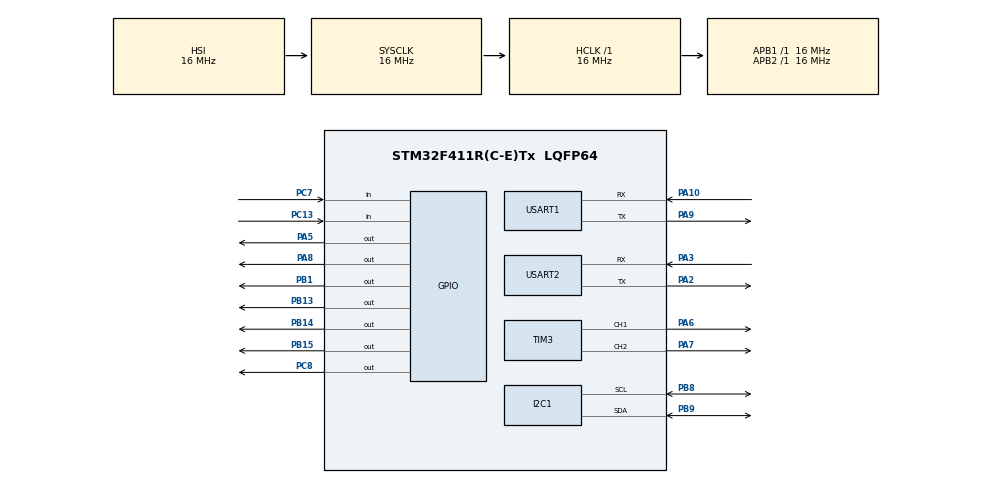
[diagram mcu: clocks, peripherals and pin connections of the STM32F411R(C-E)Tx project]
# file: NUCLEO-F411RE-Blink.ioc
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Mcu.Family=STM32F4
Mcu.Name=STM32F411R(C-E)Tx
Mcu.Package=LQFP64
NVIC.PriorityGroup=NVIC_PRIORITYGROUP_4
NVIC.USART1_IRQn=true\:0\:0\:false\:false\:true\:true\:true\:true
PA10.Mode=Asynchronous
PA10.Signal=USART1_RX
PA2.Mode=Asynchronous
PA2.Signal=USART2_TX
PA3.Mode=Asynchronous
PA3.Signal=USART2_RX
PA5.Signal=GPIO_Output
PA6.Signal=S_TIM3_CH1
PA7.Signal=S_TIM3_CH2
PA8.Signal=GPIO_Output
PA9.Mode=Asynchronous
PA9.Signal=USART1_TX
PB1.Signal=GPIO_Output
PB13.Signal=GPIO_Output
PB14.Signal=GPIO_Output
PB15.Signal=GPIO_Output
PB8.Mode=I2C
PB8.Signal=I2C1_SCL
PB9.Mode=I2C
PB9.Signal=I2C1_SDA
PC13-ANTI_TAMP.Signal=GPIO_Input
PC7.Signal=GPIO_Input
PC8.Signal=GPIO_Output
ProjectManager.HeapSize=0x200
ProjectManager.StackSize=0x400
ProjectManager.TargetToolchain=STM32CubeIDE
RCC.AHBFreq_Value=16000000
RCC.APB1Freq_Value=16000000
RCC.APB2Freq_Value=16000000
RCC.CortexFreq_Value=16000000
RCC.HSE_VALUE=25000000
RCC.HSI_VALUE=16000000
RCC.LSE_VALUE=32768
RCC.SYSCLKFreq_VALUE=16000000
RCC.VCOOutputFreq_Value=192000000
SH.S_TIM3_CH1.0=TIM3_CH1,PWM Generation1 CH1
SH.S_TIM3_CH2.0=TIM3_CH2,PWM Generation2 CH2
TIM3.Channel-PWM\ Generation1\ CH1=TIM_CHANNEL_1
TIM3.Channel-PWM\ Generation2\ CH2=TIM_CHANNEL_2
USART1.VirtualMode=VM_ASYNC
USART2.VirtualMode=VM_ASYNC
VP_TIM3_VS_ClockSourceINT.Mode=Internal
board=custom

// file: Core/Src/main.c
/* USER CODE BEGIN Header */
/**
  ******************************************************************************
  * @file           : main.c
  * @brief          : Main program body
  ******************************************************************************
  */
/* USER CODE END Header */
#include "main.h"

/* USER CODE BEGIN Includes */
#include <stdio.h>
#include <string.h>
/* USER CODE END Includes */

I2C_HandleTypeDef hi2c1;

TIM_HandleTypeDef htim3;

UART_HandleTypeDef huart1;
UART_HandleTypeDef huart2;

/* USER CODE BEGIN PV */
volatile uint8_t uart1_rx_byte;
volatile char esp32_rx_buffer[256];
volatile uint8_t esp32_rx_index = 0;
volatile uint32_t uart_rx_count = 0;
volatile char cmd_rx_buffer[256];
volatile uint8_t cmd_rx_ready = 0;

volatile int target_face_x = 0;
volatile int target_face_y = 0;
volatile int face_detected = 0;
volatile uint32_t last_face_time = 0;

// Globals for Webpage Manual Control
volatile uint32_t last_manual_command_time = 0;
volatile int manual_left_speed = 0;
volatile int manual_right_speed = 0;

// Globals for Motor Acceleration Ramping (Soft Start)
volatile int target_left_speed = 0;
volatile int target_right_speed = 0;
volatile int current_left_speed = 0;
volatile int current_right_speed = 0;

// Globals for Webpage & Screen Menu Button options
volatile uint32_t button_pressed_time = 0;
volatile uint8_t button_held = 0;
volatile uint8_t face_detect_pin_state = 1; // Default ON (sets GPIOC Pin 8 to HIGH)

uint16_t sgp30_co2 = 400;
uint16_t sgp30_tvoc = 0;
/* USER CODE END PV */

void SystemClock_Config(void);
static void MX_GPIO_Init(void);
static void MX_USART2_UART_Init(void);
static void MX_I2C1_Init(void);
static void MX_TIM3_Init(void);
static void MX_USART1_UART_Init(void);
/* USER CODE BEGIN PFP */
void set_motors(int speed_left, int speed_right);
void apply_motors(int speed_left, int speed_right);

/* USER CODE END PFP */

/* USER CODE BEGIN 0 */
typedef enum {
    EMOTION_HAPPY,
    EMOTION_ANGRY,
    EMOTION_SEARCHING,
    EMOTION_DIZZY
} RobotEmotion;

RobotEmotion current_emotion = EMOTION_HAPPY;
uint32_t last_bop_time = 0;

void DWT_Delay_us(uint32_t us) {
    // Software delay calibrated for 16MHz HSI clock
    // us * 3 is roughly 1 microsecond of delay including loop overhead
    volatile uint32_t delay = us * 3;
    while (delay--);
}

int HCSR04_Read(void) {
    HAL_GPIO_WritePin(GPIOA, GPIO_PIN_8, GPIO_PIN_RESET);
    DWT_Delay_us(2);
    HAL_GPIO_WritePin(GPIOA, GPIO_PIN_8, GPIO_PIN_SET);
    DWT_Delay_us(10);
    HAL_GPIO_WritePin(GPIOA, GPIO_PIN_8, GPIO_PIN_RESET);

    // Software timeout loop instead of DWT timer
    uint32_t timeout = 0;
    while (HAL_GPIO_ReadPin(GPIOC, GPIO_PIN_7) == GPIO_PIN_RESET) {
        if (timeout++ > 50000) return -1;
    }

    uint32_t pulse_width = 0;
    while (HAL_GPIO_ReadPin(GPIOC, GPIO_PIN_7) == GPIO_PIN_SET) {
        pulse_width++;
        // Very short delay for calibration
        volatile uint32_t delay = 2;
        while(delay--);
        if (pulse_width > 60000) return -1;
    }

    // Calibrated divisor for software loop
    return pulse_width / 25;
}

void SGP30_Init(void) {
    uint8_t cmd[2] = {0x20, 0x03};
    HAL_I2C_Master_Transmit(&hi2c1, 0x58 << 1, cmd, 2, 100);
}

void SGP30_Measure(uint16_t *co2, uint16_t *tvoc) {
    uint8_t cmd[2] = {0x20, 0x08};
    HAL_I2C_Master_Transmit(&hi2c1, 0x58 << 1, cmd, 2, 100);
    HAL_Delay(12);
    uint8_t data[6];
    if (HAL_I2C_Master_Receive(&hi2c1, 0x58 << 1, data, 6, 100) == HAL_OK) {
        *co2 = (data[0] << 8) | data[1];
        *tvoc = (data[3] << 8) | data[4];
    }
}

void set_motors(int speed_left, int speed_right) {
    target_left_speed = speed_left;
    target_right_speed = speed_right;
}

void apply_motors(int speed_left, int speed_right) {
    if (speed_left > 0) {
        HAL_GPIO_WritePin(GPIOB, GPIO_PIN_13, GPIO_PIN_SET);
        HAL_GPIO_WritePin(GPIOB, GPIO_PIN_14, GPIO_PIN_RESET);
    } else if (speed_left < 0) {
        HAL_GPIO_WritePin(GPIOB, GPIO_PIN_13, GPIO_PIN_RESET);
        HAL_GPIO_WritePin(GPIOB, GPIO_PIN_14, GPIO_PIN_SET);
        speed_left = -speed_left;
    } else {
        HAL_GPIO_WritePin(GPIOB, GPIO_PIN_13, GPIO_PIN_RESET);
        HAL_GPIO_WritePin(GPIOB, GPIO_PIN_14, GPIO_PIN_RESET);
    }

    if (speed_right > 0) {
        HAL_GPIO_WritePin(GPIOB, GPIO_PIN_15, GPIO_PIN_SET);
        HAL_GPIO_WritePin(GPIOB, GPIO_PIN_1, GPIO_PIN_RESET);
    } else if (speed_right < 0) {
        HAL_GPIO_WritePin(GPIOB, GPIO_PIN_15, GPIO_PIN_RESET);
        HAL_GPIO_WritePin(GPIOB, GPIO_PIN_1, GPIO_PIN_SET);
        speed_right = -speed_right;
    } else {
        HAL_GPIO_WritePin(GPIOB, GPIO_PIN_15, GPIO_PIN_RESET);
        HAL_GPIO_WritePin(GPIOB, GPIO_PIN_1, GPIO_PIN_RESET);
    }

    if (speed_left > 999) speed_left = 999;
    if (speed_right > 999) speed_right = 999;

    // Scale 0-1000 speed range to 0-65535 PWM period of TIM3
    uint32_t compare_left = (speed_left * 65535) / 1000;
    uint32_t compare_right = (speed_right * 65535) / 1000;

    __HAL_TIM_SET_COMPARE(&htim3, TIM_CHANNEL_1, compare_left);
    __HAL_TIM_SET_COMPARE(&htim3, TIM_CHANNEL_2, compare_right);
}

void track_face() {
    if (face_detected) {
        int error = target_face_x - 160;
        int base_speed = 300;
        int turn_speed = error * 3;
        int left = base_speed + turn_speed;
        int right = base_speed - turn_speed;
        set_motors(left, right);
    } else {
        set_motors(0, 0);
    }
}

#define OLED_ADDR        (0x3C << 1)

void OLED_WriteCommand(uint8_t cmd) {
    uint8_t buffer[2];
    buffer[0] = 0x00;
    buffer[1] = cmd;
    HAL_I2C_Master_Transmit(&hi2c1, OLED_ADDR, buffer, 2, 10);
}

void OLED_Init(void) {
    HAL_Delay(200);
    OLED_WriteCommand(0xAE);
    OLED_WriteCommand(0xD5); OLED_WriteCommand(0x80);
    OLED_WriteCommand(0xA8); OLED_WriteCommand(0x3F);
    OLED_WriteCommand(0xD3); OLED_WriteCommand(0x00);
    OLED_WriteCommand(0x40);
    OLED_WriteCommand(0x8D); OLED_WriteCommand(0x14);
    OLED_WriteCommand(0x20); OLED_WriteCommand(0x00);
    OLED_WriteCommand(0xA1);
    OLED_WriteCommand(0xC8);
    OLED_WriteCommand(0xDA); OLED_WriteCommand(0x12);
    OLED_WriteCommand(0x81); OLED_WriteCommand(0x7F);
    OLED_WriteCommand(0xD9); OLED_WriteCommand(0x22);
    OLED_WriteCommand(0xDB); OLED_WriteCommand(0x20);
    OLED_WriteCommand(0xA4); OLED_WriteCommand(0xA6);
    OLED_WriteCommand(0xAF);
    HAL_Delay(10);
}

void OLED_Clear(void) {
    OLED_WriteCommand(0x21); OLED_WriteCommand(0); OLED_WriteCommand(127);
    OLED_WriteCommand(0x22); OLED_WriteCommand(0); OLED_WriteCommand(7);
    static uint8_t clear_buf[129];
    clear_buf[0] = 0x40;
    for(int i = 1; i <= 128; i++) clear_buf[i] = 0x00;
    for(int page = 0; page < 8; page++) {
        HAL_I2C_Master_Transmit(&hi2c1, OLED_ADDR, clear_buf, 129, 50);
    }
}

const uint8_t BasicFont[41][5] = {
    {0x3E, 0x51, 0x49, 0x45, 0x3E}, // 0
    {0x00, 0x42, 0x7F, 0x40, 0x00}, // 1
    {0x42, 0x61, 0x51, 0x49, 0x46}, // 2
    {0x21, 0x41, 0x45, 0x4B, 0x31}, // 3
    {0x18, 0x14, 0x12, 0x7F, 0x10}, // 4
    {0x27, 0x45, 0x45, 0x45, 0x39}, // 5
    {0x3C, 0x4A, 0x49, 0x49, 0x30}, // 6
    {0x01, 0x71, 0x09, 0x05, 0x03}, // 7
    {0x36, 0x49, 0x49, 0x49, 0x36}, // 8
    {0x06, 0x49, 0x49, 0x29, 0x1E}, // 9
    {0x7E, 0x11, 0x11, 0x11, 0x7E}, // A
    {0x7F, 0x49, 0x49, 0x49, 0x36}, // B
    {0x3E, 0x41, 0x41, 0x41, 0x22}, // C
    {0x7F, 0x41, 0x41, 0x22, 0x1C}, // D
    {0x7F, 0x49, 0x49, 0x49, 0x41}, // E
    {0x7F, 0x09, 0x09, 0x09, 0x01}, // F
    {0x3E, 0x41, 0x49, 0x49, 0x7A}, // G
    {0x7F, 0x08, 0x08, 0x08, 0x7F}, // H
    {0x00, 0x41, 0x7F, 0x41, 0x00}, // I
    {0x20, 0x40, 0x41, 0x3F, 0x01}, // J
    {0x7F, 0x08, 0x14, 0x22, 0x41}, // K
    {0x7F, 0x40, 0x40, 0x40, 0x40}, // L
    {0x7F, 0x02, 0x0C, 0x02, 0x7F}, // M
    {0x7F, 0x04, 0x08, 0x10, 0x7F}, // N
    {0x3E, 0x41, 0x41, 0x41, 0x3E}, // O
    {0x7F, 0x09, 0x09, 0x09, 0x06}, // P
    {0x3E, 0x41, 0x51, 0x21, 0x5E}, // Q
    {0x7F, 0x09, 0x19, 0x29, 0x46}, // R
    {0x46, 0x49, 0x49, 0x49, 0x31}, // S
    {0x01, 0x01, 0x7F, 0x01, 0x01}, // T
    {0x3F, 0x40, 0x40, 0x40, 0x3F}, // U
    {0x00, 0x20, 0x40, 0x20, 0x00}, // V
    {0x3F, 0x40, 0x38, 0x40, 0x3F}, // W
    {0x63, 0x14, 0x08, 0x14, 0x63}, // X
    {0x07, 0x08, 0x70, 0x08, 0x07}, // Y
    {0x61, 0x51, 0x49, 0x45, 0x43}, // Z
    {0x00, 0x00, 0x00, 0x00, 0x00}, // [Space]
    {0x00, 0x24, 0x24, 0x24, 0x00}, // :
    {0x08, 0x08, 0x08, 0x08, 0x08}, // -
    {0x41, 0x22, 0x14, 0x08, 0x00}, // >
    {0x08, 0x14, 0x22, 0x41, 0x00}  // <
};

void OLED_PrintText(uint8_t page, uint8_t col, char* str) {
    OLED_WriteCommand(0x21); OLED_WriteCommand(col); OLED_WriteCommand(127);
    OLED_WriteCommand(0x22); OLED_WriteCommand(page); OLED_WriteCommand(7);
    static uint8_t tx_buf[6];
    tx_buf[0] = 0x40;
    while(*str) {
        uint8_t idx = 36;
        char c = *str;
        if (c >= '0' && c <= '9') idx = c - '0';
        else if (c >= 'A' && c <= 'Z') idx = (c - 'A') + 10;
        else if (c >= 'a' && c <= 'z') idx = (c - 'a') + 10;
        else if (c == ':') idx = 37;
        else if (c == '-') idx = 38;
        else if (c == '>') idx = 39;
        else if (c == '<') idx = 40;
        for(int i = 0; i < 5; i++) tx_buf[i + 1] = BasicFont[idx][i];
        HAL_I2C_Master_Transmit(&hi2c1, OLED_ADDR, tx_buf, 6, 10);
        str++;
    }
}

void OLED_DrawBitmap(const uint8_t* bitmap) {
    OLED_WriteCommand(0x21); OLED_WriteCommand(0); OLED_WriteCommand(127);
    OLED_WriteCommand(0x22); OLED_WriteCommand(0); OLED_WriteCommand(7);
    static uint8_t data_buffer[1025];
    data_buffer[0] = 0x40;
    for (int i = 0; i < 1024; i++) {
        data_buffer[i + 1] = bitmap[i];
    }
    HAL_I2C_Master_Transmit(&hi2c1, OLED_ADDR, data_buffer, 1025, 200);
}

// Your updated text canvas mathematically padded to a solid 64 rows and converted to vertical page bytes
const uint8_t OLED_TrueDogBitmap[1024] = {
	0x00, 0x00, 0x00, 0x00, 0x00, 0x00, 0x00, 0x00, 0x00, 0x00, 0x00, 0x00, 0x00, 0x00, 0x00, 0x00,
	0x00, 0x00, 0x00, 0x00, 0x00, 0x00, 0x00, 0x00, 0x00, 0x00, 0x00, 0x00, 0x00, 0x00, 0x00, 0x00,
	0x00, 0x00, 0x00, 0x00, 0x00, 0x00, 0x00, 0x00, 0x00, 0x00, 0x00, 0x00, 0x00, 0x00, 0x00, 0x00,
	0x00, 0x00, 0x00, 0x00, 0x00, 0x00, 0x00, 0x00, 0x00, 0x00, 0x00, 0x00, 0x00, 0x00, 0x00, 0x00,
	0x00, 0x00, 0x00, 0x00, 0x00, 0x00, 0x00, 0x00, 0x00, 0x00, 0x00, 0x00, 0x00, 0x00, 0x00, 0x00,
	0x00, 0x00, 0x00, 0x00, 0x00, 0x00, 0x00, 0x00, 0x00, 0x00, 0x00, 0x00, 0x00, 0x00, 0x00, 0x00,
	0x00, 0x00, 0x00, 0x00, 0x00, 0x00, 0x00, 0x00, 0x00, 0x00, 0x00, 0x00, 0x00, 0x00, 0x00, 0x00,
	0x00, 0x00, 0x00, 0x00, 0x00, 0x00, 0x00, 0x00, 0x00, 0x00, 0x00, 0x00, 0x00, 0x00, 0x00, 0x00,
	0x00, 0x00, 0x00, 0x00, 0x00, 0x00, 0x00, 0x00, 0x00, 0x00, 0x00, 0x00, 0x00, 0x00, 0x00, 0x00,
	0x00, 0x00, 0x00, 0x00, 0x00, 0x00, 0x00, 0x00, 0x00, 0x00, 0x00, 0x00, 0x00, 0x00, 0x00, 0x00,
	0x00, 0x00, 0x00, 0x00, 0x00, 0x00, 0x00, 0x00, 0x00, 0x00, 0x00, 0x00, 0x00, 0x00, 0x00, 0x00,
	0x00, 0x00, 0x00, 0x00, 0x00, 0x00, 0x00, 0x00, 0x00, 0x00, 0x00, 0x00, 0x00, 0x00, 0x00, 0x00,
	0x00, 0x00, 0x00, 0x00, 0x00, 0x00, 0x00, 0x00, 0x00, 0x00, 0x00, 0x00, 0x00, 0x00, 0x00, 0x00,
	0x00, 0x00, 0xE0, 0xE0, 0xE0, 0xE0, 0xE0, 0xE0, 0xE0, 0xE0, 0xE0, 0xE0, 0xE0, 0xE0, 0xE0, 0xE0,
	0xE0, 0xE0, 0xE0, 0xE0, 0xE0, 0xE0, 0xE0, 0xE0, 0xE0, 0xE0, 0x00, 0x00, 0x00, 0x00, 0x00, 0x00,
	0x00, 0x00, 0x00, 0x00, 0x00, 0x00, 0x00, 0x00, 0x00, 0x00, 0x00, 0x00, 0x00, 0x00, 0x00, 0x00,
	0x00, 0x00, 0x00, 0x00, 0x00, 0x00, 0x00, 0x00, 0x00, 0x00, 0x00, 0x00, 0x00, 0x00, 0x00, 0x80,
	0x80, 0x80, 0x80, 0x80, 0x80, 0x80, 0x80, 0x80, 0xE0, 0xE0, 0xF0, 0xF0, 0xF0, 0xFF, 0x7F, 0x7F,
	0x7F, 0x7F, 0xFF, 0xFC, 0xFC, 0xFC, 0xFC, 0xFC, 0xFC, 0xFC, 0xFC, 0xFC, 0x83, 0x83, 0x83, 0x83,
	0xFF, 0xFF, 0xFF, 0xFF, 0xFF, 0xFF, 0x00, 0x00, 0x00, 0x00, 0x00, 0x00, 0x00, 0x00, 0x00, 0x00,
	0x00, 0x00, 0x00, 0x00, 0x00, 0x00, 0x00, 0x00, 0xFC, 0xFC, 0xFC, 0xFC, 0xFC, 0xFF, 0xFF, 0xFF,
	0xFF, 0xFF, 0xFF, 0x1F, 0x1F, 0x1F, 0x1F, 0x07, 0x07, 0x07, 0x07, 0x07, 0x07, 0x07, 0x07, 0x07,
	0x1F, 0x1F, 0x1F, 0x1F, 0x1F, 0x7F, 0x7F, 0x7F, 0x7F, 0x7F, 0x7F, 0x7F, 0x7F, 0x7F, 0x7F, 0x00,
	0x00, 0x00, 0x00, 0x00, 0x00, 0x00, 0x00, 0x00, 0x00, 0x00, 0x00, 0x00, 0x00, 0x00, 0x00, 0x00,
	0x00, 0x00, 0x00, 0x00, 0x00, 0x00, 0x00, 0x00, 0x00, 0x00, 0x00, 0x00, 0x00, 0x00, 0x00, 0x7F,
	0x3F, 0x3F, 0x3F, 0xFF, 0xFF, 0xFF, 0xFF, 0xFF, 0xFF, 0xFF, 0xFF, 0xFF, 0xFF, 0xFF, 0xF0, 0xF0,
	0xF0, 0xF0, 0xFF, 0xFF, 0xFF, 0xFF, 0xFF, 0xFF, 0xFF, 0xFF, 0xFF, 0xFF, 0xFF, 0xFF, 0xFF, 0xFF,
	0xFF, 0x7F, 0x7F, 0x7F, 0x7F, 0xFF, 0xC0, 0xC0, 0xC0, 0xC0, 0xC0, 0x00, 0x00, 0x00, 0x00, 0x00,
	0x00, 0x00, 0x00, 0x00, 0x00, 0x00, 0x00, 0x00, 0x0F, 0x0F, 0x0F, 0x0F, 0x0F, 0x7F, 0x7F, 0x7F,
	0x7F, 0x7F, 0xFF, 0xF0, 0xF0, 0xF0, 0xF0, 0xC0, 0xC0, 0xC0, 0xC0, 0xC0, 0x00, 0x00, 0x00, 0x00,
	0x00, 0x00, 0x00, 0x00, 0x00, 0x00, 0x00, 0x00, 0x00, 0x00, 0x00, 0x00, 0x00, 0x00, 0x00, 0x00,
	0x00, 0x00, 0x00, 0x00, 0x00, 0x00, 0x00, 0x00, 0x00, 0x00, 0x00, 0x00, 0x00, 0x00, 0x00, 0x00,
	0x00, 0x00, 0x00, 0x00, 0x00, 0x00, 0x00, 0x00, 0x00, 0x00, 0x00, 0x00, 0x00, 0x00, 0x00, 0x00,
	0x00, 0x00, 0x00, 0x01, 0x01, 0x01, 0x01, 0x01, 0x01, 0x01, 0x01, 0x01, 0x01, 0x01, 0x01, 0x01,
	0x01, 0x01, 0xF9, 0xF9, 0xF9, 0xF9, 0xF9, 0xF9, 0xF9, 0xF9, 0xF9, 0xF9, 0xF9, 0xF9, 0xF9, 0xF9,
	0xFF, 0xFE, 0xFE, 0xFE, 0xFF, 0xFF, 0xFF, 0xFF, 0xFF, 0xFF, 0xFF, 0xFE, 0xFE, 0xFE, 0xFE, 0xFE,
	0xFE, 0xFE, 0xFE, 0xFE, 0xFE, 0xFE, 0xFE, 0xFE, 0xFE, 0xFE, 0xFE, 0xFE, 0xFE, 0xFE, 0xFE, 0xFE,
	0xFE, 0xFE, 0xFF, 0xFF, 0xFF, 0xFF, 0xFF, 0xFF, 0xFF, 0xFF, 0xFF, 0xFF, 0xFF, 0xFE, 0xFE, 0xFE,
	0xFE, 0x00, 0x00, 0x00, 0x00, 0x00, 0x00, 0x00, 0x00, 0x00, 0x00, 0x00, 0x00, 0x00, 0x00, 0x00,
	0x00, 0x00, 0x00, 0x00, 0x00, 0x00, 0x00, 0x00, 0x00, 0x00, 0x00, 0x00, 0x00, 0x00, 0x00, 0x00,
	0x00, 0x00, 0x00, 0x00, 0x00, 0x00, 0x00, 0x00, 0x00, 0x00, 0x00, 0x00, 0x00, 0x00, 0x00, 0x00,
	0x00, 0x00, 0x00, 0x00, 0x00, 0x00, 0x00, 0x00, 0x00, 0x00, 0x00, 0x00, 0x00, 0x00, 0x00, 0x00,
	0x00, 0x00, 0x00, 0x00, 0x00, 0x00, 0x00, 0xFF, 0xFF, 0xFF, 0xFF, 0xFF, 0x07, 0x07, 0x07, 0x07,
	0x7F, 0x7F, 0x7F, 0x7F, 0x7F, 0xFF, 0xFF, 0xFF, 0xFF, 0xFF, 0xFF, 0x1F, 0x1F, 0x1F, 0x9F, 0x9F,
	0x9F, 0x9F, 0x9F, 0x9F, 0x9F, 0x9F, 0x9F, 0x9F, 0xFF, 0x7F, 0x7F, 0x7F, 0x7F, 0xFF, 0xFF, 0xFF,
	0xFF, 0xFF, 0xFF, 0xFF, 0xFF, 0xFF, 0xFF, 0x7F, 0x7F, 0x7F, 0x7F, 0x7F, 0x1F, 0x1F, 0x1F, 0x1F,
	0x1F, 0x00, 0x00, 0x00, 0x00, 0x00, 0x00, 0x00, 0x00, 0x00, 0x00, 0x00, 0x00, 0x00, 0x00, 0x00,
	0x00, 0x00, 0x00, 0x00, 0x00, 0x00, 0x00, 0x00, 0x00, 0x00, 0x00, 0x00, 0x00, 0x00, 0x00, 0x00,
	0x00, 0x00, 0x00, 0x00, 0x00, 0x00, 0x00, 0x00, 0x00, 0x00, 0x00, 0x00, 0x00, 0x00, 0x00, 0x00,
	0x00, 0x00, 0x00, 0x00, 0x00, 0x00, 0x00, 0x00, 0x00, 0x00, 0x00, 0x00, 0x00, 0x00, 0x00, 0x00,
	0x00, 0x00, 0x70, 0x70, 0x70, 0x70, 0x70, 0x0F, 0x0F, 0x0F, 0x0F, 0x0F, 0x00, 0x00, 0x00, 0x00,
	0x00, 0x00, 0x00, 0x00, 0x00, 0x7F, 0x7F, 0x7F, 0x7F, 0x7F, 0x3F, 0x00, 0x00, 0x00, 0x01, 0x73,
	0x73, 0x73, 0x73, 0x7F, 0x0F, 0x0F, 0x0F, 0x0F, 0x0F, 0x00, 0x00, 0x00, 0x00, 0x03, 0x03, 0x03,
	0x03, 0x03, 0x0F, 0x0F, 0x0F, 0x0F, 0x3F, 0x7E, 0x7E, 0x7E, 0x7E, 0x7E, 0x00, 0x00, 0x00, 0x00,
	0x00, 0x00, 0x00, 0x00, 0x00, 0x00, 0x00, 0x00, 0x00, 0x00, 0x00, 0x00, 0x00, 0x00, 0x00, 0x00,
	0x00, 0x00, 0x00, 0x00, 0x00, 0x00, 0x00, 0x00, 0x00, 0x00, 0x00, 0x00, 0x00, 0x00, 0x00, 0x00,
	0x00, 0x00, 0x00, 0x00, 0x00, 0x00, 0x00, 0x00, 0x00, 0x00, 0x00, 0x00, 0x00, 0x00, 0x00, 0x00,
	0x00, 0x00, 0x00, 0x00, 0x00, 0x00, 0x00, 0x00, 0x00, 0x00, 0x00, 0x00, 0x00, 0x00, 0x00, 0x00,
	0x00, 0x00, 0x00, 0x00, 0x00, 0x00, 0x00, 0x00, 0x00, 0x00, 0x00, 0x00, 0x00, 0x00, 0x00, 0x00,
	0x00, 0x00, 0x00, 0x00, 0x00, 0x00, 0x00, 0x00, 0x00, 0x00, 0x00, 0x00, 0x00, 0x00, 0x00, 0x00,
	0x00, 0x00, 0x00, 0x00, 0x00, 0x00, 0x00, 0x00, 0x00, 0x00, 0x00, 0x00, 0x00, 0x00, 0x00, 0x00,
	0x00, 0x00, 0x00, 0x00, 0x00, 0x00, 0x00, 0x00, 0x00, 0x00, 0x00, 0x00, 0x00, 0x00, 0x00, 0x00,
};

const uint8_t OLED_AngryBitmap[] = {
	0x00, 0x00, 0x00, 0x00, 0x00, 0x00, 0x00, 0x00, 0x00, 0x00, 0x00, 0x00, 0x00, 0x00, 0x00, 0x00,
	0x00, 0x00, 0x00, 0x00, 0x00, 0x00, 0x00, 0x00, 0x00, 0x00, 0x00, 0x00, 0x00, 0x00, 0x00, 0x00,
	0x00, 0x00, 0x00, 0x00, 0x00, 0x00, 0x00, 0x00, 0x00, 0x00, 0x00, 0x00, 0x00, 0x00, 0x00, 0x00,
	0x00, 0x00, 0x00, 0x00, 0x00, 0x00, 0x00, 0x00, 0x00, 0x00, 0x00, 0x00, 0x00, 0x00, 0x00, 0x00,
	0x00, 0x00, 0x00, 0x00, 0x00, 0x00, 0x00, 0x00, 0x00, 0x00, 0x00, 0x00, 0x00, 0x00, 0x00, 0x00,
	0x00, 0x00, 0x00, 0x00, 0x00, 0x00, 0x00, 0x00, 0x00, 0x00, 0x00, 0x00, 0x00, 0x00, 0x00, 0x00,
	0x00, 0x00, 0x00, 0x00, 0x00, 0x00, 0x00, 0x00, 0x00, 0x00, 0x00, 0x00, 0x00, 0x00, 0x00, 0x00,
	0x00, 0x00, 0x00, 0x00, 0x00, 0x00, 0x00, 0x00, 0x00, 0x00, 0x00, 0x00, 0x00, 0x00, 0x00, 0x00,
	0x00, 0x00, 0x00, 0x00, 0x00, 0x00, 0x00, 0x00, 0x00, 0x00, 0x00, 0x00, 0x00, 0x00, 0x00, 0x00,
	0x00, 0x00, 0x00, 0x00, 0x00, 0x00, 0x00, 0x00, 0x00, 0x00, 0x00, 0x00, 0x00, 0x00, 0x00, 0x00,
	0x00, 0x00, 0x00, 0x00, 0x00, 0x00, 0x00, 0x00, 0x00, 0x00, 0x00, 0x00, 0x00, 0x00, 0x00, 0x00,
	0x00, 0x00, 0x00, 0x00, 0x00, 0x00, 0x00, 0x00, 0x00, 0x00, 0x00, 0x00, 0x00, 0x00, 0x00, 0x00,
	0x00, 0x00, 0x00, 0x00, 0x00, 0x00, 0x00, 0x00, 0x00, 0x00, 0x00, 0x00, 0x00, 0x00, 0x00, 0x00,
	0x00, 0x00, 0x00, 0x00, 0x00, 0x00, 0x00, 0x00, 0x00, 0x00, 0x00, 0x00, 0x00, 0x00, 0x00, 0x00,
	0x00, 0x00, 0x00, 0x00, 0x00, 0x00, 0x00, 0x00, 0x00, 0x00, 0x00, 0x00, 0x00, 0x00, 0x00, 0x00,
	0x00, 0x00, 0x00, 0x00, 0x00, 0x00, 0x00, 0x00, 0x00, 0x00, 0x00, 0x00, 0x00, 0x00, 0x00, 0x00,
	0x00, 0x00, 0x00, 0x00, 0x00, 0x00, 0x00, 0x00, 0x00, 0x00, 0x00, 0x00, 0x00, 0x00, 0x00, 0x00,
	0x00, 0x00, 0x00, 0x00, 0x00, 0x00, 0x00, 0x00, 0x00, 0x00, 0x00, 0x00, 0x00, 0x00, 0x00, 0x00,
	0x00, 0x00, 0x00, 0x00, 0x00, 0x00, 0x00, 0x00, 0x00, 0x00, 0x00, 0x80, 0x80, 0xC0, 0xC0, 0xE0,
	0x60, 0x70, 0x30, 0x00, 0x00, 0x00, 0x00, 0x00, 0x00, 0x00, 0x00, 0x00, 0x00, 0x00, 0x00, 0x00,
	0x00, 0x00, 0x00, 0x00, 0x00, 0x00, 0x00, 0x00, 0x00, 0x00, 0x00, 0x00, 0x00, 0x00, 0x00, 0x30,
	0x70, 0x60, 0xE0, 0xC0, 0xC0, 0x80, 0x80, 0x00, 0x00, 0x00, 0x00, 0x00, 0x00, 0x00, 0x00, 0x00,
	0x00, 0x00, 0x00, 0x00, 0x00, 0x00, 0x00, 0x00, 0x00, 0x00, 0x00, 0x00, 0x00, 0x00, 0x00, 0x00,
	0x00, 0x00, 0x00, 0x00, 0x00, 0x00, 0x00, 0x00, 0x00, 0x00, 0x00, 0x00, 0x00, 0x00, 0x00, 0x00,
	0x00, 0x00, 0x00, 0x00, 0x00, 0x00, 0x00, 0x00, 0x00, 0x00, 0x00, 0x00, 0x00, 0x00, 0x00, 0x00,
	0x00, 0x00, 0x00, 0x00, 0x00, 0x00, 0x00, 0x00, 0x00, 0x00, 0x00, 0x00, 0x00, 0x00, 0xC0, 0xE0,
	0xE0, 0xF0, 0xF0, 0xF8, 0xD8, 0xDC, 0xCC, 0xCE, 0xC6, 0xC7, 0xC3, 0xC3, 0xC1, 0xC1, 0xC0, 0xC0,
	0xC0, 0xC0, 0x00, 0x00, 0x00, 0x00, 0x00, 0x00, 0x00, 0x00, 0x00, 0x00, 0x00, 0x00, 0x00, 0x00,
	0x00, 0x00, 0x00, 0x00, 0x00, 0x00, 0x00, 0x00, 0x00, 0x00, 0x00, 0x00, 0x00, 0x00, 0xC0, 0xC0,
	0xC0, 0xC0, 0xC0, 0xC0, 0xC1, 0xC1, 0xC3, 0xC3, 0xC7, 0xC6, 0xCE, 0xCC, 0xDC, 0xD8, 0xF8, 0xF0,
	0xF0, 0xE0, 0xE0, 0xC0, 0x00, 0x00, 0x00, 0x00, 0x00, 0x00, 0x00, 0x00, 0x00, 0x00, 0x00, 0x00,
	0x00, 0x00, 0x00, 0x00, 0x00, 0x00, 0x00, 0x00, 0x00, 0x00, 0x00, 0x00, 0x00, 0x00, 0x00, 0x00,
	0x00, 0x00, 0x00, 0x00, 0x00, 0x00, 0x00, 0x00, 0x00, 0x00, 0x00, 0x00, 0x00, 0x00, 0x00, 0x00,
	0x00, 0x00, 0x00, 0x00, 0x00, 0x00, 0x00, 0x00, 0x00, 0x00, 0x00, 0x00, 0x00, 0x00, 0xFF, 0xFF,
	0xFF, 0xFF, 0xFF, 0xFF, 0xFF, 0xFF, 0xFF, 0xFF, 0xFF, 0xFF, 0xFF, 0xFF, 0xFF, 0xFF, 0xFF, 0xFF,
	0xFF, 0xFF, 0x00, 0x00, 0x00, 0x00, 0x00, 0x00, 0x00, 0x00, 0x00, 0x00, 0x00, 0x00, 0x00, 0x00,
	0x00, 0x00, 0x00, 0x00, 0x00, 0x00, 0x00, 0x00, 0x00, 0x00, 0x00, 0x00, 0x00, 0x00, 0xFF, 0xFF,
	0xFF, 0xFF, 0xFF, 0xFF, 0xFF, 0xFF, 0xFF, 0xFF, 0xFF, 0xFF, 0xFF, 0xFF, 0xFF, 0xFF, 0xFF, 0xFF,
	0xFF, 0xFF, 0x00, 0x00, 0x00, 0x00, 0x00, 0x00, 0x00, 0x00, 0x00, 0x00, 0x00, 0x00, 0x00, 0x00,
	0x00, 0x00, 0x00, 0x00, 0x00, 0x00, 0x00, 0x00, 0x00, 0x00, 0x00, 0x00, 0x00, 0x00, 0x00, 0x00,
	0x00, 0x00, 0x00, 0x00, 0x00, 0x00, 0x00, 0x00, 0x00, 0x00, 0x00, 0x00, 0x00, 0x00, 0x00, 0x00,
	0x00, 0x00, 0x00, 0x00, 0x00, 0x00, 0x00, 0x00, 0x00, 0x00, 0x00, 0x00, 0x00, 0x00, 0x00, 0x00,
	0x00, 0x00, 0x00, 0x00, 0x00, 0x00, 0x00, 0x00, 0x00, 0x00, 0x00, 0x00, 0x00, 0x00, 0x00, 0x00,
	0x00, 0x00, 0x00, 0x00, 0x00, 0x00, 0x00, 0x00, 0x00, 0x00, 0x00, 0x00, 0x00, 0x00, 0x00, 0x00,
	0x00, 0x00, 0x00, 0x00, 0x00, 0x00, 0x00, 0x00, 0x00, 0x00, 0x00, 0x00, 0x00, 0x00, 0x00, 0x00,
	0x00, 0x00, 0x00, 0x00, 0x00, 0x00, 0x00, 0x00, 0x00, 0x00, 0x00, 0x00, 0x00, 0x00, 0x00, 0x00,
	0x00, 0x00, 0x00, 0x00, 0x00, 0x00, 0x00, 0x00, 0x00, 0x00, 0x00, 0x00, 0x00, 0x00, 0x00, 0x00,
	0x00, 0x00, 0x00, 0x00, 0x00, 0x00, 0x00, 0x00, 0x00, 0x00, 0x00, 0x00, 0x00, 0x00, 0x00, 0x00,
	0x00, 0x00, 0x00, 0x00, 0x00, 0x00, 0x00, 0x00, 0x00, 0x00, 0x00, 0x00, 0x00, 0x00, 0x00, 0x00,
	0x00, 0x00, 0x00, 0x00, 0x00, 0x00, 0x00, 0x00, 0x00, 0x00, 0x00, 0x00, 0x00, 0x00, 0x00, 0x00,
	0x00, 0x00, 0x00, 0x00, 0x00, 0x00, 0x00, 0x00, 0x00, 0x00, 0x00, 0x00, 0x00, 0x00, 0x00, 0x00,
	0x00, 0x00, 0x00, 0x00, 0x00, 0x00, 0x00, 0x00, 0x00, 0x00, 0x00, 0x00, 0x00, 0x00, 0x00, 0x00,
	0x00, 0x00, 0x00, 0x00, 0x00, 0x00, 0x0C, 0x0C, 0x0C, 0x0C, 0x0C, 0x0C, 0x0C, 0x0C, 0x0C, 0x0C,
	0x0C, 0x0C, 0x0C, 0x0C, 0x0C, 0x0C, 0x0C, 0x0C, 0x0C, 0x0C, 0x00, 0x00, 0x00, 0x00, 0x00, 0x00,
	0x00, 0x00, 0x00, 0x00, 0x00, 0x00, 0x00, 0x00, 0x00, 0x00, 0x00, 0x00, 0x00, 0x00, 0x00, 0x00,
	0x00, 0x00, 0x00, 0x00, 0x00, 0x00, 0x00, 0x00, 0x00, 0x00, 0x00, 0x00, 0x00, 0x00, 0x00, 0x00,
	0x00, 0x00, 0x00, 0x00, 0x00, 0x00, 0x00, 0x00, 0x00, 0x00, 0x00, 0x00, 0x00, 0x00, 0x00, 0x00,
	0x00, 0x00, 0x00, 0x00, 0x00, 0x00, 0x00, 0x00, 0x00, 0x00, 0x00, 0x00, 0x00, 0x00, 0x00, 0x00,
	0x00, 0x00, 0x00, 0x00, 0x00, 0x00, 0x00, 0x00, 0x00, 0x00, 0x00, 0x00, 0x00, 0x00, 0x00, 0x00,
	0x00, 0x00, 0x00, 0x00, 0x00, 0x00, 0x00, 0x00, 0x00, 0x00, 0x00, 0x00, 0x00, 0x00, 0x00, 0x00,
	0x00, 0x00, 0x00, 0x00, 0x00, 0x00, 0x00, 0x00, 0x00, 0x00, 0x00, 0x00, 0x00, 0x00, 0x00, 0x00,
	0x00, 0x00, 0x00, 0x00, 0x00, 0x00, 0x00, 0x00, 0x00, 0x00, 0x00, 0x00, 0x00, 0x00, 0x00, 0x00,
	0x00, 0x00, 0x00, 0x00, 0x00, 0x00, 0x00, 0x00, 0x00, 0x00, 0x00, 0x00, 0x00, 0x00, 0x00, 0x00,
	0x00, 0x00, 0x00, 0x00, 0x00, 0x00, 0x00, 0x00, 0x00, 0x00, 0x00, 0x00, 0x00, 0x00, 0x00, 0x00,
	0x00, 0x00, 0x00, 0x00, 0x00, 0x00, 0x00, 0x00, 0x00, 0x00, 0x00, 0x00, 0x00, 0x00, 0x00, 0x00
};
const uint8_t OLED_SmileBitmap[1024] = {
	0x00, 0x00, 0x00, 0x00, 0x00, 0x00, 0x00, 0x00, 0x00, 0x00, 0x00, 0x00, 0x00, 0x00, 0x00, 0x00,
	0x00, 0x00, 0x00, 0x00, 0x00, 0x00, 0x00, 0x00, 0x00, 0x00, 0x00, 0x00, 0x00, 0x00, 0x00, 0x00,
	0x00, 0x00, 0x00, 0x00, 0x00, 0x00, 0x00, 0x00, 0x00, 0x00, 0x00, 0x00, 0x00, 0x00, 0x00, 0x00,
	0x00, 0x00, 0x00, 0x00, 0x00, 0x00, 0x00, 0x00, 0x00, 0x00, 0x00, 0x00, 0x00, 0x00, 0x00, 0x00,
	0x00, 0x00, 0x00, 0x00, 0x00, 0x00, 0x00, 0x00, 0x00, 0x00, 0x00, 0x00, 0x00, 0x00, 0x00, 0x00,
	0x00, 0x00, 0x00, 0x00, 0x00, 0x00, 0x00, 0x00, 0x00, 0x00, 0x00, 0x00, 0x00, 0x00, 0x00, 0x00,
	0x00, 0x00, 0x00, 0x00, 0x00, 0x00, 0x00, 0x00, 0x00, 0x00, 0x00, 0x00, 0x00, 0x00, 0x00, 0x00,
	0x00, 0x00, 0x00, 0x00, 0x00, 0x00, 0x00, 0x00, 0x00, 0x00, 0x00, 0x00, 0x00, 0x00, 0x00, 0x00,
	0x00, 0x00, 0x00, 0x00, 0x00, 0x00, 0x00, 0x00, 0x00, 0x00, 0x00, 0x00, 0x00, 0x00, 0x00, 0x00,
	0x00, 0x00, 0x00, 0x00, 0x00, 0x00, 0x00, 0x00, 0x00, 0x00, 0x00, 0x00, 0x00, 0x00, 0x00, 0x00,
	0x00, 0x00, 0x00, 0x00, 0x00, 0x00, 0x00, 0x00, 0x00, 0x00, 0x00, 0x00, 0x00, 0x00, 0x00, 0x00,
	0x00, 0x00, 0x00, 0x00, 0x00, 0x00, 0x00, 0x00, 0x00, 0x00, 0x00, 0x00, 0x00, 0x00, 0x00, 0x00,
	0x00, 0x00, 0x00, 0x00, 0x00, 0x00, 0x00, 0x00, 0x00, 0x00, 0x00, 0x00, 0x00, 0x00, 0x00, 0x00,
	0x00, 0x00, 0x00, 0x00, 0x00, 0x00, 0x00, 0x00, 0x00, 0x00, 0x00, 0x00, 0x00, 0x00, 0x00, 0x00,
	0x00, 0x00, 0x00, 0x00, 0x00, 0x00, 0x00, 0x00, 0x00, 0x00, 0x00, 0x00, 0x00, 0x00, 0x00, 0x00,
	0x00, 0x00, 0x00, 0x00, 0x00, 0x00, 0x00, 0x00, 0x00, 0x00, 0x00, 0x00, 0x00, 0x00, 0x00, 0x00,
	0x00, 0x00, 0x00, 0x00, 0x00, 0x00, 0x00, 0x00, 0x00, 0x00, 0x00, 0x00, 0x00, 0x00, 0x00, 0x00,
	0x00, 0x00, 0x00, 0x00, 0x00, 0x00, 0x00, 0x00, 0x00, 0x00, 0x00, 0x00, 0x00, 0x00, 0x00, 0x00,
	0x00, 0x80, 0x80, 0xC0, 0xC0, 0xE0, 0xE0, 0x70, 0x70, 0x70, 0xE0, 0xE0, 0xC0, 0xC0, 0x80, 0x80,
	0x00, 0x00, 0x00, 0x00, 0x00, 0x00, 0x00, 0x00, 0x00, 0x00, 0x00, 0x00, 0x00, 0x00, 0x00, 0x00,
	0x00, 0x00, 0x00, 0x00, 0x00, 0x00, 0x00, 0x00, 0x00, 0x00, 0x00, 0x00, 0x00, 0x00, 0x00, 0x00,
	0x00, 0x80, 0x80, 0xC0, 0xC0, 0xE0, 0xE0, 0x70, 0x70, 0x70, 0xE0, 0xE0, 0xC0, 0xC0, 0x80, 0x80,
	0x00, 0x00, 0x00, 0x00, 0x00, 0x00, 0x00, 0x00, 0x00, 0x00, 0x00, 0x00, 0x00, 0x00, 0x00, 0x00,
	0x00, 0x00, 0x00, 0x00, 0x00, 0x00, 0x00, 0x00, 0x00, 0x00, 0x00, 0x00, 0x00, 0x00, 0x00, 0x00,
	0x00, 0x00, 0x00, 0x00, 0x00, 0x00, 0x00, 0x00, 0x00, 0x00, 0x00, 0x00, 0x00, 0x00, 0x00, 0x00,
	0x00, 0x00, 0x00, 0x00, 0x00, 0x00, 0x00, 0x00, 0x00, 0x00, 0x00, 0x00, 0x00, 0x00, 0x0E, 0x07,
	0x07, 0x03, 0x03, 0x01, 0x01, 0x00, 0x00, 0x00, 0x00, 0x00, 0x00, 0x00, 0x01, 0x01, 0x03, 0x03,
	0x07, 0x07, 0x00, 0x00, 0x00, 0x00, 0x00, 0x00, 0x00, 0x00, 0x00, 0x00, 0x00, 0x00, 0x00, 0x00,
	0x00, 0x00, 0x00, 0x00, 0x00, 0x00, 0x00, 0x00, 0x00, 0x00, 0x00, 0x00, 0x00, 0x00, 0x0E, 0x07,
	0x07, 0x03, 0x03, 0x01, 0x01, 0x00, 0x00, 0x00, 0x00, 0x00, 0x00, 0x00, 0x01, 0x01, 0x03, 0x03,
	0x07, 0x07, 0x00, 0x00, 0x00, 0x00, 0x00, 0x00, 0x00, 0x00, 0x00, 0x00, 0x00, 0x00, 0x00, 0x00,
	0x00, 0x00, 0x00, 0x00, 0x00, 0x00, 0x00, 0x00, 0x00, 0x00, 0x00, 0x00, 0x00, 0x00, 0x00, 0x00,
	0x00, 0x00, 0x00, 0x00, 0x00, 0x00, 0x00, 0x00, 0x00, 0x00, 0x00, 0x00, 0x00, 0x00, 0x00, 0x00,
	0x00, 0x00, 0x00, 0x00, 0x00, 0x00, 0x00, 0x00, 0x00, 0x00, 0x00, 0x00, 0x00, 0x00, 0x00, 0x00,
	0x00, 0x00, 0x00, 0x00, 0x00, 0x00, 0x00, 0x00, 0x00, 0x00, 0x00, 0x00, 0x00, 0x00, 0x00, 0x00,
	0x00, 0x00, 0x00, 0x00, 0x00, 0x00, 0x00, 0x00, 0x00, 0x00, 0x00, 0x00, 0x00, 0x00, 0x00, 0x00,
	0x00, 0x00, 0x00, 0x00, 0x00, 0x00, 0x00, 0x00, 0x00, 0x00, 0x00, 0x00, 0x00, 0x00, 0x00, 0x00,
	0x00, 0x00, 0x00, 0x00, 0x00, 0x00, 0x00, 0x00, 0x00, 0x00, 0x00, 0x00, 0x00, 0x00, 0x00, 0x00,
	0x00, 0x00, 0x00, 0x00, 0x00, 0x00, 0x00, 0x00, 0x00, 0x00, 0x00, 0x00, 0x00, 0x00, 0x00, 0x00,
	0x00, 0x00, 0x00, 0x00, 0x00, 0x00, 0x00, 0x00, 0x00, 0x00, 0x00, 0x00, 0x00, 0x00, 0x00, 0x00,
	0x00, 0x00, 0x00, 0x00, 0x00, 0x00, 0x00, 0x00, 0x00, 0x00, 0x00, 0x00, 0x00, 0x00, 0x00, 0x00,
	0x00, 0x00, 0x00, 0x00, 0x00, 0x00, 0x00, 0x00, 0x00, 0x00, 0x00, 0x00, 0x00, 0x00, 0x00, 0x00,
	0x00, 0x00, 0x00, 0x00, 0x00, 0x00, 0x00, 0x00, 0x00, 0x00, 0x00, 0x00, 0x07, 0x07, 0x0E, 0x0E,
	0x1C, 0x1C, 0x38, 0x38, 0x70, 0x70, 0xE0, 0xE0, 0xC0, 0xC0, 0x80, 0x80, 0x00, 0x00, 0x00, 0x00,
	0x00, 0x00, 0x00, 0x00, 0x00, 0x80, 0x80, 0xC0, 0xC0, 0xE0, 0xE0, 0x70, 0x70, 0x38, 0x38, 0x1C,
	0x1C, 0x0E, 0x0E, 0x07, 0x00, 0x00, 0x00, 0x00, 0x00, 0x00, 0x00, 0x00, 0x00, 0x00, 0x00, 0x00,
	0x00, 0x00, 0x00, 0x00, 0x00, 0x00, 0x00, 0x00, 0x00, 0x00, 0x00, 0x00, 0x00, 0x00, 0x00, 0x00,
	0x00, 0x00, 0x00, 0x00, 0x00, 0x00, 0x00, 0x00, 0x00, 0x00, 0x00, 0x00, 0x00, 0x00, 0x00, 0x00,
	0x00, 0x00, 0x00, 0x00, 0x00, 0x00, 0x00, 0x00, 0x00, 0x00, 0x00, 0x00, 0x00, 0x00, 0x00, 0x00,
	0x00, 0x00, 0x00, 0x00, 0x00, 0x00, 0x00, 0x00, 0x00, 0x00, 0x00, 0x00, 0x00, 0x00, 0x00, 0x00,
	0x00, 0x00, 0x00, 0x00, 0x00, 0x00, 0x00, 0x00, 0x00, 0x00, 0x00, 0x00, 0x00, 0x00, 0x00, 0x00,
	0x00, 0x00, 0x00, 0x00, 0x00, 0x00, 0x00, 0x00, 0x01, 0x01, 0x03, 0x03, 0x07, 0x07, 0x0E, 0x0E,
	0x1C, 0x0E, 0x0E, 0x07, 0x07, 0x03, 0x03, 0x01, 0x01, 0x00, 0x00, 0x00, 0x00, 0x00, 0x00, 0x00,
	0x00, 0x00, 0x00, 0x00, 0x00, 0x00, 0x00, 0x00, 0x00, 0x00, 0x00, 0x00, 0x00, 0x00, 0x00, 0x00,
	0x00, 0x00, 0x00, 0x00, 0x00, 0x00, 0x00, 0x00, 0x00, 0x00, 0x00, 0x00, 0x00, 0x00, 0x00, 0x00,
	0x00, 0x00, 0x00, 0x00, 0x00, 0x00, 0x00, 0x00, 0x00, 0x00, 0x00, 0x00, 0x00, 0x00, 0x00, 0x00,
	0x00, 0x00, 0x00, 0x00, 0x00, 0x00, 0x00, 0x00, 0x00, 0x00, 0x00, 0x00, 0x00, 0x00, 0x00, 0x00,
	0x00, 0x00, 0x00, 0x00, 0x00, 0x00, 0x00, 0x00, 0x00, 0x00, 0x00, 0x00, 0x00, 0x00, 0x00, 0x00,
	0x00, 0x00, 0x00, 0x00, 0x00, 0x00, 0x00, 0x00, 0x00, 0x00, 0x00, 0x00, 0x00, 0x00, 0x00, 0x00,
	0x00, 0x00, 0x00, 0x00, 0x00, 0x00, 0x00, 0x00, 0x00, 0x00, 0x00, 0x00, 0x00, 0x00, 0x00, 0x00,
	0x00, 0x00, 0x00, 0x00, 0x00, 0x00, 0x00, 0x00, 0x00, 0x00, 0x00, 0x00, 0x00, 0x00, 0x00, 0x00,
	0x00, 0x00, 0x00, 0x00, 0x00, 0x00, 0x00, 0x00, 0x00, 0x00, 0x00, 0x00, 0x00, 0x00, 0x00, 0x00,
	0x00, 0x00, 0x00, 0x00, 0x00, 0x00, 0x00, 0x00, 0x00, 0x00, 0x00, 0x00, 0x00, 0x00, 0x00, 0x00,
	0x00, 0x00, 0x00, 0x00, 0x00, 0x00, 0x00, 0x00, 0x00, 0x00, 0x00, 0x00, 0x00, 0x00, 0x00, 0x00
};
const uint8_t OLED_LookLeftBitmap[1024] = {
	0x00, 0x00, 0x00, 0x00, 0x00, 0x00, 0x00, 0x00, 0x00, 0x00, 0x00, 0x00, 0x00, 0x00, 0x00, 0x00,
	0x00, 0x00, 0x00, 0x00, 0x00, 0x00, 0x00, 0x00, 0x00, 0x00, 0x00, 0x00, 0x00, 0x00, 0x00, 0x00,
	0x00, 0x00, 0x00, 0x00, 0x00, 0x00, 0x00, 0x00, 0x00, 0x00, 0x00, 0x00, 0x00, 0x00, 0x00, 0x00,
	0x00, 0x00, 0x00, 0x00, 0x00, 0x00, 0x00, 0x00, 0x00, 0x00, 0x00, 0x00, 0x00, 0x00, 0x00, 0x00,
	0x00, 0x00, 0x00, 0x00, 0x00, 0x00, 0x00, 0x00, 0x00, 0x00, 0x00, 0x00, 0x00, 0x00, 0x00, 0x00,
	0x00, 0x00, 0x00, 0x00, 0x00, 0x00, 0x00, 0x00, 0x00, 0x00, 0x00, 0x00, 0x00, 0x00, 0x00, 0x00,
	0x00, 0x00, 0x00, 0x00, 0x00, 0x00, 0x00, 0x00, 0x00, 0x00, 0x00, 0x00, 0x00, 0x00, 0x00, 0x00,
	0x00, 0x00, 0x00, 0x00, 0x00, 0x00, 0x00, 0x00, 0x00, 0x00, 0x00, 0x00, 0x00, 0x00, 0x00, 0x00,
	0x00, 0x00, 0x00, 0x00, 0x00, 0x00, 0x00, 0x00, 0x00, 0x00, 0x00, 0x00, 0x00, 0x00, 0x00, 0x00,
	0x00, 0x00, 0x00, 0x00, 0x00, 0x00, 0x00, 0x00, 0x00, 0x00, 0x00, 0x00, 0x00, 0x00, 0x00, 0x00,
	0x00, 0x00, 0x00, 0x00, 0x00, 0x00, 0x00, 0x00, 0x00, 0x00, 0x00, 0x00, 0x00, 0x00, 0x00, 0x00,
	0x00, 0x00, 0x00, 0x00, 0x00, 0x00, 0x00, 0x00, 0x00, 0x00, 0x00, 0x00, 0x00, 0x00, 0x00, 0x00,
	0x00, 0x00, 0x00, 0x00, 0x00, 0x00, 0x00, 0x00, 0x00, 0x00, 0x00, 0x00, 0x00, 0x00, 0x00, 0x00,
	0x00, 0x00, 0x00, 0x00, 0x00, 0x00, 0x00, 0x00, 0x00, 0x00, 0x00, 0x00, 0x00, 0x00, 0x00, 0x00,
	0x00, 0x00, 0x00, 0x00, 0x00, 0x00, 0x00, 0x00, 0x00, 0x00, 0x00, 0x00, 0x00, 0x00, 0x00, 0x00,
	0x00, 0x00, 0x00, 0x00, 0x00, 0x00, 0x00, 0x00, 0x00, 0x00, 0x00, 0x00, 0x00, 0x00, 0x00, 0x00,
	0x00, 0x00, 0x00, 0x00, 0x00, 0x00, 0x00, 0x00, 0x00, 0x00, 0x00, 0x00, 0x00, 0x00, 0x00, 0x00,
	0x00, 0x00, 0x00, 0x00, 0x00, 0x00, 0x00, 0x00, 0x00, 0x00, 0x00, 0x00, 0x00, 0x00, 0xF0, 0xF0,
	0x30, 0x30, 0x30, 0x30, 0x30, 0x30, 0x30, 0x30, 0x30, 0x30, 0x30, 0x30, 0x30, 0x30, 0x30, 0x30,
	0xF0, 0xF0, 0x00, 0x00, 0x00, 0x00, 0x00, 0x00, 0x00, 0x00, 0x00, 0x00, 0x00, 0x00, 0x00, 0x00,
	0x00, 0x00, 0x00, 0x00, 0x00, 0x00, 0x00, 0x00, 0x00, 0x00, 0x00, 0x00, 0x00, 0x00, 0xF0, 0xF0,
	0x30, 0x30, 0x30, 0x30, 0x30, 0x30, 0x30, 0x30, 0x30, 0x30, 0x30, 0x30, 0x30, 0x30, 0x30, 0x30,
	0xF0, 0xF0, 0x00, 0x00, 0x00, 0x00, 0x00, 0x00, 0x00, 0x00, 0x00, 0x00, 0x00, 0x00, 0x00, 0x00,
	0x00, 0x00, 0x00, 0x00, 0x00, 0x00, 0x00, 0x00, 0x00, 0x00, 0x00, 0x00, 0x00, 0x00, 0x00, 0x00,
	0x00, 0x00, 0x00, 0x00, 0x00, 0x00, 0x00, 0x00, 0x00, 0x00, 0x00, 0x00, 0x00, 0x00, 0x00, 0x00,
	0x00, 0x00, 0x00, 0x00, 0x00, 0x00, 0x00, 0x00, 0x00, 0x00, 0x00, 0x00, 0x00, 0x00, 0xFF, 0xFF,
	0x00, 0xF8, 0xF8, 0xF8, 0xF8, 0xF8, 0xF8, 0x00, 0x00, 0x00, 0x00, 0x00, 0x00, 0x00, 0x00, 0x00,
	0xFF, 0xFF, 0x00, 0x00, 0x00, 0x00, 0x00, 0x00, 0x00, 0x00, 0x00, 0x00, 0x00, 0x00, 0x00, 0x00,
	0x00, 0x00, 0x00, 0x00, 0x00, 0x00, 0x00, 0x00, 0x00, 0x00, 0x00, 0x00, 0x00, 0x00, 0xFF, 0xFF,
	0x00, 0xF8, 0xF8, 0xF8, 0xF8, 0xF8, 0xF8, 0x00, 0x00, 0x00, 0x00, 0x00, 0x00, 0x00, 0x00, 0x00,
	0xFF, 0xFF, 0x00, 0x00, 0x00, 0x00, 0x00, 0x00, 0x00, 0x00, 0x00, 0x00, 0x00, 0x00, 0x00, 0x00,
	0x00, 0x00, 0x00, 0x00, 0x00, 0x00, 0x00, 0x00, 0x00, 0x00, 0x00, 0x00, 0x00, 0x00, 0x00, 0x00,
	0x00, 0x00, 0x00, 0x00, 0x00, 0x00, 0x00, 0x00, 0x00, 0x00, 0x00, 0x00, 0x00, 0x00, 0x00, 0x00,
	0x00, 0x00, 0x00, 0x00, 0x00, 0x00, 0x00, 0x00, 0x00, 0x00, 0x00, 0x00, 0x00, 0x00, 0xFF, 0xFF,
	0xC0, 0xC1, 0xC1, 0xC1, 0xC1, 0xC1, 0xC1, 0xC0, 0xC0, 0xC0, 0xC0, 0xC0, 0xC0, 0xC0, 0xC0, 0xC0,
	0xFF, 0xFF, 0x00, 0x00, 0x00, 0x00, 0x00, 0x00, 0x00, 0x00, 0x00, 0x00, 0x00, 0x00, 0x00, 0x00,
	0x00, 0x00, 0x00, 0x00, 0x00, 0x00, 0x00, 0x00, 0x00, 0x00, 0x00, 0x00, 0x00, 0x00, 0xFF, 0xFF,
	0xC0, 0xC1, 0xC1, 0xC1, 0xC1, 0xC1, 0xC1, 0xC0, 0xC0, 0xC0, 0xC0, 0xC0, 0xC0, 0xC0, 0xC0, 0xC0,
	0xFF, 0xFF, 0x00, 0x00, 0x00, 0x00, 0x00, 0x00, 0x00, 0x00, 0x00, 0x00, 0x00, 0x00, 0x00, 0x00,
	0x00, 0x00, 0x00, 0x00, 0x00, 0x00, 0x00, 0x00, 0x00, 0x00, 0x00, 0x00, 0x00, 0x00, 0x00, 0x00,
	0x00, 0x00, 0x00, 0x00, 0x00, 0x00, 0x00, 0x00, 0x00, 0x00, 0x00, 0x00, 0x00, 0x00, 0x00, 0x00,
	0x00, 0x00, 0x00, 0x00, 0x00, 0x00, 0x00, 0x00, 0x00, 0x00, 0x00, 0x00, 0x00, 0x00, 0x00, 0x00,
	0x00, 0x00, 0x00, 0x00, 0x00, 0x00, 0x00, 0x00, 0x00, 0x00, 0x00, 0x00, 0x00, 0x00, 0x00, 0x00,
	0x00, 0x00, 0x00, 0x00, 0x00, 0x00, 0x00, 0x00, 0x00, 0x00, 0x00, 0x00, 0x00, 0x00, 0x00, 0x00,
	0x00, 0x00, 0x00, 0x00, 0x00, 0x00, 0x00, 0x00, 0x00, 0x00, 0x00, 0x00, 0x00, 0x00, 0x00, 0x00,
	0x00, 0x00, 0x00, 0x00, 0x00, 0x00, 0x00, 0x00, 0x00, 0x00, 0x00, 0x00, 0x00, 0x00, 0x00, 0x00,
	0x00, 0x00, 0x00, 0x00, 0x00, 0x00, 0x00, 0x00, 0x00, 0x00, 0x00, 0x00, 0x00, 0x00, 0x00, 0x00,
	0x00, 0x00, 0x00, 0x00, 0x00, 0x00, 0x00, 0x00, 0x00, 0x00, 0x00, 0x00, 0x00, 0x00, 0x00, 0x00,
	0x00, 0x00, 0x00, 0x00, 0x00, 0x00, 0x00, 0x00, 0x00, 0x00, 0x00, 0x00, 0x00, 0x00, 0x00, 0x00,
	0x00, 0x00, 0x00, 0x00, 0x00, 0x00, 0x00, 0x00, 0x00, 0x00, 0x00, 0x00, 0x00, 0x00, 0x00, 0x00,
	0x00, 0x00, 0x00, 0x00, 0x00, 0x00, 0x00, 0x00, 0x00, 0x00, 0x00, 0x00, 0x00, 0x00, 0x00, 0x00,
	0x00, 0x00, 0x00, 0x00, 0x00, 0x00, 0x00, 0x00, 0x00, 0x00, 0x00, 0x00, 0x0C, 0x0C, 0x0C, 0x0C,
	0x0C, 0x0C, 0x0C, 0x0C, 0x00, 0x00, 0x00, 0x00, 0x00, 0x00, 0x00, 0x00, 0x00, 0x00, 0x00, 0x00,
	0x00, 0x00, 0x00, 0x00, 0x00, 0x00, 0x00, 0x00, 0x00, 0x00, 0x00, 0x00, 0x00, 0x00, 0x00, 0x00,
	0x00, 0x00, 0x00, 0x00, 0x00, 0x00, 0x00, 0x00, 0x00, 0x00, 0x00, 0x00, 0x00, 0x00, 0x00, 0x00,
	0x00, 0x00, 0x00, 0x00, 0x00, 0x00, 0x00, 0x00, 0x00, 0x00, 0x00, 0x00, 0x00, 0x00, 0x00, 0x00,
	0x00, 0x00, 0x00, 0x00, 0x00, 0x00, 0x00, 0x00, 0x00, 0x00, 0x00, 0x00, 0x00, 0x00, 0x00, 0x00,
	0x00, 0x00, 0x00, 0x00, 0x00, 0x00, 0x00, 0x00, 0x00, 0x00, 0x00, 0x00, 0x00, 0x00, 0x00, 0x00,
	0x00, 0x00, 0x00, 0x00, 0x00, 0x00, 0x00, 0x00, 0x00, 0x00, 0x00, 0x00, 0x00, 0x00, 0x00, 0x00,
	0x00, 0x00, 0x00, 0x00, 0x00, 0x00, 0x00, 0x00, 0x00, 0x00, 0x00, 0x00, 0x00, 0x00, 0x00, 0x00,
	0x00, 0x00, 0x00, 0x00, 0x00, 0x00, 0x00, 0x00, 0x00, 0x00, 0x00, 0x00, 0x00, 0x00, 0x00, 0x00,
	0x00, 0x00, 0x00, 0x00, 0x00, 0x00, 0x00, 0x00, 0x00, 0x00, 0x00, 0x00, 0x00, 0x00, 0x00, 0x00,
	0x00, 0x00, 0x00, 0x00, 0x00, 0x00, 0x00, 0x00, 0x00, 0x00, 0x00, 0x00, 0x00, 0x00, 0x00, 0x00,
	0x00, 0x00, 0x00, 0x00, 0x00, 0x00, 0x00, 0x00, 0x00, 0x00, 0x00, 0x00, 0x00, 0x00, 0x00, 0x00
};
const uint8_t OLED_LookCenterBitmap[1024] = {
	0x00, 0x00, 0x00, 0x00, 0x00, 0x00, 0x00, 0x00, 0x00, 0x00, 0x00, 0x00, 0x00, 0x00, 0x00, 0x00,
	0x00, 0x00, 0x00, 0x00, 0x00, 0x00, 0x00, 0x00, 0x00, 0x00, 0x00, 0x00, 0x00, 0x00, 0x00, 0x00,
	0x00, 0x00, 0x00, 0x00, 0x00, 0x00, 0x00, 0x00, 0x00, 0x00, 0x00, 0x00, 0x00, 0x00, 0x00, 0x00,
	0x00, 0x00, 0x00, 0x00, 0x00, 0x00, 0x00, 0x00, 0x00, 0x00, 0x00, 0x00, 0x00, 0x00, 0x00, 0x00,
	0x00, 0x00, 0x00, 0x00, 0x00, 0x00, 0x00, 0x00, 0x00, 0x00, 0x00, 0x00, 0x00, 0x00, 0x00, 0x00,
	0x00, 0x00, 0x00, 0x00, 0x00, 0x00, 0x00, 0x00, 0x00, 0x00, 0x00, 0x00, 0x00, 0x00, 0x00, 0x00,
	0x00, 0x00, 0x00, 0x00, 0x00, 0x00, 0x00, 0x00, 0x00, 0x00, 0x00, 0x00, 0x00, 0x00, 0x00, 0x00,
	0x00, 0x00, 0x00, 0x00, 0x00, 0x00, 0x00, 0x00, 0x00, 0x00, 0x00, 0x00, 0x00, 0x00, 0x00, 0x00,
	0x00, 0x00, 0x00, 0x00, 0x00, 0x00, 0x00, 0x00, 0x00, 0x00, 0x00, 0x00, 0x00, 0x00, 0x00, 0x00,
	0x00, 0x00, 0x00, 0x00, 0x00, 0x00, 0x00, 0x00, 0x00, 0x00, 0x00, 0x00, 0x00, 0x00, 0x00, 0x00,
	0x00, 0x00, 0x00, 0x00, 0x00, 0x00, 0x00, 0x00, 0x00, 0x00, 0x00, 0x00, 0x00, 0x00, 0x00, 0x00,
	0x00, 0x00, 0x00, 0x00, 0x00, 0x00, 0x00, 0x00, 0x00, 0x00, 0x00, 0x00, 0x00, 0x00, 0x00, 0x00,
	0x00, 0x00, 0x00, 0x00, 0x00, 0x00, 0x00, 0x00, 0x00, 0x00, 0x00, 0x00, 0x00, 0x00, 0x00, 0x00,
	0x00, 0x00, 0x00, 0x00, 0x00, 0x00, 0x00, 0x00, 0x00, 0x00, 0x00, 0x00, 0x00, 0x00, 0x00, 0x00,
	0x00, 0x00, 0x00, 0x00, 0x00, 0x00, 0x00, 0x00, 0x00, 0x00, 0x00, 0x00, 0x00, 0x00, 0x00, 0x00,
	0x00, 0x00, 0x00, 0x00, 0x00, 0x00, 0x00, 0x00, 0x00, 0x00, 0x00, 0x00, 0x00, 0x00, 0x00, 0x00,
	0x00, 0x00, 0x00, 0x00, 0x00, 0x00, 0x00, 0x00, 0x00, 0x00, 0x00, 0x00, 0x00, 0x00, 0x00, 0x00,
	0x00, 0x00, 0x00, 0x00, 0x00, 0x00, 0x00, 0x00, 0x00, 0x00, 0x00, 0x00, 0x00, 0x00, 0xF0, 0xF0,
	0x30, 0x30, 0x30, 0x30, 0x30, 0x30, 0x30, 0x30, 0x30, 0x30, 0x30, 0x30, 0x30, 0x30, 0x30, 0x30,
	0xF0, 0xF0, 0x00, 0x00, 0x00, 0x00, 0x00, 0x00, 0x00, 0x00, 0x00, 0x00, 0x00, 0x00, 0x00, 0x00,
	0x00, 0x00, 0x00, 0x00, 0x00, 0x00, 0x00, 0x00, 0x00, 0x00, 0x00, 0x00, 0x00, 0x00, 0xF0, 0xF0,
	0x30, 0x30, 0x30, 0x30, 0x30, 0x30, 0x30, 0x30, 0x30, 0x30, 0x30, 0x30, 0x30, 0x30, 0x30, 0x30,
	0xF0, 0xF0, 0x00, 0x00, 0x00, 0x00, 0x00, 0x00, 0x00, 0x00, 0x00, 0x00, 0x00, 0x00, 0x00, 0x00,
	0x00, 0x00, 0x00, 0x00, 0x00, 0x00, 0x00, 0x00, 0x00, 0x00, 0x00, 0x00, 0x00, 0x00, 0x00, 0x00,
	0x00, 0x00, 0x00, 0x00, 0x00, 0x00, 0x00, 0x00, 0x00, 0x00, 0x00, 0x00, 0x00, 0x00, 0x00, 0x00,
	0x00, 0x00, 0x00, 0x00, 0x00, 0x00, 0x00, 0x00, 0x00, 0x00, 0x00, 0x00, 0x00, 0x00, 0xFF, 0xFF,
	0x00, 0x00, 0x00, 0x00, 0x00, 0xF8, 0xF8, 0xF8, 0xF8, 0xF8, 0xF8, 0x00, 0x00, 0x00, 0x00, 0x00,
	0xFF, 0xFF, 0x00, 0x00, 0x00, 0x00, 0x00, 0x00, 0x00, 0x00, 0x00, 0x00, 0x00, 0x00, 0x00, 0x00,
	0x00, 0x00, 0x00, 0x00, 0x00, 0x00, 0x00, 0x00, 0x00, 0x00, 0x00, 0x00, 0x00, 0x00, 0xFF, 0xFF,
	0x00, 0x00, 0x00, 0x00, 0x00, 0xF8, 0xF8, 0xF8, 0xF8, 0xF8, 0xF8, 0x00, 0x00, 0x00, 0x00, 0x00,
	0xFF, 0xFF, 0x00, 0x00, 0x00, 0x00, 0x00, 0x00, 0x00, 0x00, 0x00, 0x00, 0x00, 0x00, 0x00, 0x00,
	0x00, 0x00, 0x00, 0x00, 0x00, 0x00, 0x00, 0x00, 0x00, 0x00, 0x00, 0x00, 0x00, 0x00, 0x00, 0x00,
	0x00, 0x00, 0x00, 0x00, 0x00, 0x00, 0x00, 0x00, 0x00, 0x00, 0x00, 0x00, 0x00, 0x00, 0x00, 0x00,
	0x00, 0x00, 0x00, 0x00, 0x00, 0x00, 0x00, 0x00, 0x00, 0x00, 0x00, 0x00, 0x00, 0x00, 0xFF, 0xFF,
	0xC0, 0xC0, 0xC0, 0xC0, 0xC0, 0xC1, 0xC1, 0xC1, 0xC1, 0xC1, 0xC1, 0xC0, 0xC0, 0xC0, 0xC0, 0xC0,
	0xFF, 0xFF, 0x00, 0x00, 0x00, 0x00, 0x00, 0x00, 0x00, 0x00, 0x00, 0x00, 0x00, 0x00, 0x00, 0x00,
	0x00, 0x00, 0x00, 0x00, 0x00, 0x00, 0x00, 0x00, 0x00, 0x00, 0x00, 0x00, 0x00, 0x00, 0xFF, 0xFF,
	0xC0, 0xC0, 0xC0, 0xC0, 0xC0, 0xC1, 0xC1, 0xC1, 0xC1, 0xC1, 0xC1, 0xC0, 0xC0, 0xC0, 0xC0, 0xC0,
	0xFF, 0xFF, 0x00, 0x00, 0x00, 0x00, 0x00, 0x00, 0x00, 0x00, 0x00, 0x00, 0x00, 0x00, 0x00, 0x00,
	0x00, 0x00, 0x00, 0x00, 0x00, 0x00, 0x00, 0x00, 0x00, 0x00, 0x00, 0x00, 0x00, 0x00, 0x00, 0x00,
	0x00, 0x00, 0x00, 0x00, 0x00, 0x00, 0x00, 0x00, 0x00, 0x00, 0x00, 0x00, 0x00, 0x00, 0x00, 0x00,
	0x00, 0x00, 0x00, 0x00, 0x00, 0x00, 0x00, 0x00, 0x00, 0x00, 0x00, 0x00, 0x00, 0x00, 0x00, 0x00,
	0x00, 0x00, 0x00, 0x00, 0x00, 0x00, 0x00, 0x00, 0x00, 0x00, 0x00, 0x00, 0x00, 0x00, 0x00, 0x00,
	0x00, 0x00, 0x00, 0x00, 0x00, 0x00, 0x00, 0x00, 0x00, 0x00, 0x00, 0x00, 0x00, 0x00, 0x00, 0x00,
	0x00, 0x00, 0x00, 0x00, 0x00, 0x00, 0x00, 0x00, 0x00, 0x00, 0x00, 0x00, 0x00, 0x00, 0x00, 0x00,
	0x00, 0x00, 0x00, 0x00, 0x00, 0x00, 0x00, 0x00, 0x00, 0x00, 0x00, 0x00, 0x00, 0x00, 0x00, 0x00,
	0x00, 0x00, 0x00, 0x00, 0x00, 0x00, 0x00, 0x00, 0x00, 0x00, 0x00, 0x00, 0x00, 0x00, 0x00, 0x00,
	0x00, 0x00, 0x00, 0x00, 0x00, 0x00, 0x00, 0x00, 0x00, 0x00, 0x00, 0x00, 0x00, 0x00, 0x00, 0x00,
	0x00, 0x00, 0x00, 0x00, 0x00, 0x00, 0x00, 0x00, 0x00, 0x00, 0x00, 0x00, 0x00, 0x00, 0x00, 0x00,
	0x00, 0x00, 0x00, 0x00, 0x00, 0x00, 0x00, 0x00, 0x00, 0x00, 0x00, 0x00, 0x00, 0x00, 0x00, 0x00,
	0x00, 0x00, 0x00, 0x00, 0x00, 0x00, 0x00, 0x00, 0x00, 0x00, 0x00, 0x00, 0x00, 0x00, 0x00, 0x00,
	0x00, 0x00, 0x00, 0x00, 0x00, 0x00, 0x00, 0x00, 0x00, 0x00, 0x00, 0x00, 0x0C, 0x0C, 0x0C, 0x0C,
	0x0C, 0x0C, 0x0C, 0x0C, 0x00, 0x00, 0x00, 0x00, 0x00, 0x00, 0x00, 0x00, 0x00, 0x00, 0x00, 0x00,
	0x00, 0x00, 0x00, 0x00, 0x00, 0x00, 0x00, 0x00, 0x00, 0x00, 0x00, 0x00, 0x00, 0x00, 0x00, 0x00,
	0x00, 0x00, 0x00, 0x00, 0x00, 0x00, 0x00, 0x00, 0x00, 0x00, 0x00, 0x00, 0x00, 0x00, 0x00, 0x00,
	0x00, 0x00, 0x00, 0x00, 0x00, 0x00, 0x00, 0x00, 0x00, 0x00, 0x00, 0x00, 0x00, 0x00, 0x00, 0x00,
	0x00, 0x00, 0x00, 0x00, 0x00, 0x00, 0x00, 0x00, 0x00, 0x00, 0x00, 0x00, 0x00, 0x00, 0x00, 0x00,
	0x00, 0x00, 0x00, 0x00, 0x00, 0x00, 0x00, 0x00, 0x00, 0x00, 0x00, 0x00, 0x00, 0x00, 0x00, 0x00,
	0x00, 0x00, 0x00, 0x00, 0x00, 0x00, 0x00, 0x00, 0x00, 0x00, 0x00, 0x00, 0x00, 0x00, 0x00, 0x00,
	0x00, 0x00, 0x00, 0x00, 0x00, 0x00, 0x00, 0x00, 0x00, 0x00, 0x00, 0x00, 0x00, 0x00, 0x00, 0x00,
	0x00, 0x00, 0x00, 0x00, 0x00, 0x00, 0x00, 0x00, 0x00, 0x00, 0x00, 0x00, 0x00, 0x00, 0x00, 0x00,
	0x00, 0x00, 0x00, 0x00, 0x00, 0x00, 0x00, 0x00, 0x00, 0x00, 0x00, 0x00, 0x00, 0x00, 0x00, 0x00,
	0x00, 0x00, 0x00, 0x00, 0x00, 0x00, 0x00, 0x00, 0x00, 0x00, 0x00, 0x00, 0x00, 0x00, 0x00, 0x00,
	0x00, 0x00, 0x00, 0x00, 0x00, 0x00, 0x00, 0x00, 0x00, 0x00, 0x00, 0x00, 0x00, 0x00, 0x00, 0x00
};
const uint8_t OLED_LookRightBitmap[1024] = {
	0x00, 0x00, 0x00, 0x00, 0x00, 0x00, 0x00, 0x00, 0x00, 0x00, 0x00, 0x00, 0x00, 0x00, 0x00, 0x00,
	0x00, 0x00, 0x00, 0x00, 0x00, 0x00, 0x00, 0x00, 0x00, 0x00, 0x00, 0x00, 0x00, 0x00, 0x00, 0x00,
	0x00, 0x00, 0x00, 0x00, 0x00, 0x00, 0x00, 0x00, 0x00, 0x00, 0x00, 0x00, 0x00, 0x00, 0x00, 0x00,
	0x00, 0x00, 0x00, 0x00, 0x00, 0x00, 0x00, 0x00, 0x00, 0x00, 0x00, 0x00, 0x00, 0x00, 0x00, 0x00,
	0x00, 0x00, 0x00, 0x00, 0x00, 0x00, 0x00, 0x00, 0x00, 0x00, 0x00, 0x00, 0x00, 0x00, 0x00, 0x00,
	0x00, 0x00, 0x00, 0x00, 0x00, 0x00, 0x00, 0x00, 0x00, 0x00, 0x00, 0x00, 0x00, 0x00, 0x00, 0x00,
	0x00, 0x00, 0x00, 0x00, 0x00, 0x00, 0x00, 0x00, 0x00, 0x00, 0x00, 0x00, 0x00, 0x00, 0x00, 0x00,
	0x00, 0x00, 0x00, 0x00, 0x00, 0x00, 0x00, 0x00, 0x00, 0x00, 0x00, 0x00, 0x00, 0x00, 0x00, 0x00,
	0x00, 0x00, 0x00, 0x00, 0x00, 0x00, 0x00, 0x00, 0x00, 0x00, 0x00, 0x00, 0x00, 0x00, 0x00, 0x00,
	0x00, 0x00, 0x00, 0x00, 0x00, 0x00, 0x00, 0x00, 0x00, 0x00, 0x00, 0x00, 0x00, 0x00, 0x00, 0x00,
	0x00, 0x00, 0x00, 0x00, 0x00, 0x00, 0x00, 0x00, 0x00, 0x00, 0x00, 0x00, 0x00, 0x00, 0x00, 0x00,
	0x00, 0x00, 0x00, 0x00, 0x00, 0x00, 0x00, 0x00, 0x00, 0x00, 0x00, 0x00, 0x00, 0x00, 0x00, 0x00,
	0x00, 0x00, 0x00, 0x00, 0x00, 0x00, 0x00, 0x00, 0x00, 0x00, 0x00, 0x00, 0x00, 0x00, 0x00, 0x00,
	0x00, 0x00, 0x00, 0x00, 0x00, 0x00, 0x00, 0x00, 0x00, 0x00, 0x00, 0x00, 0x00, 0x00, 0x00, 0x00,
	0x00, 0x00, 0x00, 0x00, 0x00, 0x00, 0x00, 0x00, 0x00, 0x00, 0x00, 0x00, 0x00, 0x00, 0x00, 0x00,
	0x00, 0x00, 0x00, 0x00, 0x00, 0x00, 0x00, 0x00, 0x00, 0x00, 0x00, 0x00, 0x00, 0x00, 0x00, 0x00,
	0x00, 0x00, 0x00, 0x00, 0x00, 0x00, 0x00, 0x00, 0x00, 0x00, 0x00, 0x00, 0x00, 0x00, 0x00, 0x00,
	0x00, 0x00, 0x00, 0x00, 0x00, 0x00, 0x00, 0x00, 0x00, 0x00, 0x00, 0x00, 0x00, 0x00, 0xF0, 0xF0,
	0x30, 0x30, 0x30, 0x30, 0x30, 0x30, 0x30, 0x30, 0x30, 0x30, 0x30, 0x30, 0x30, 0x30, 0x30, 0x30,
	0xF0, 0xF0, 0x00, 0x00, 0x00, 0x00, 0x00, 0x00, 0x00, 0x00, 0x00, 0x00, 0x00, 0x00, 0x00, 0x00,
	0x00, 0x00, 0x00, 0x00, 0x00, 0x00, 0x00, 0x00, 0x00, 0x00, 0x00, 0x00, 0x00, 0x00, 0xF0, 0xF0,
	0x30, 0x30, 0x30, 0x30, 0x30, 0x30, 0x30, 0x30, 0x30, 0x30, 0x30, 0x30, 0x30, 0x30, 0x30, 0x30,
	0xF0, 0xF0, 0x00, 0x00, 0x00, 0x00, 0x00, 0x00, 0x00, 0x00, 0x00, 0x00, 0x00, 0x00, 0x00, 0x00,
	0x00, 0x00, 0x00, 0x00, 0x00, 0x00, 0x00, 0x00, 0x00, 0x00, 0x00, 0x00, 0x00, 0x00, 0x00, 0x00,
	0x00, 0x00, 0x00, 0x00, 0x00, 0x00, 0x00, 0x00, 0x00, 0x00, 0x00, 0x00, 0x00, 0x00, 0x00, 0x00,
	0x00, 0x00, 0x00, 0x00, 0x00, 0x00, 0x00, 0x00, 0x00, 0x00, 0x00, 0x00, 0x00, 0x00, 0xFF, 0xFF,
	0x00, 0x00, 0x00, 0x00, 0x00, 0x00, 0x00, 0x00, 0x00, 0xF8, 0xF8, 0xF8, 0xF8, 0xF8, 0xF8, 0x00,
	0xFF, 0xFF, 0x00, 0x00, 0x00, 0x00, 0x00, 0x00, 0x00, 0x00, 0x00, 0x00, 0x00, 0x00, 0x00, 0x00,
	0x00, 0x00, 0x00, 0x00, 0x00, 0x00, 0x00, 0x00, 0x00, 0x00, 0x00, 0x00, 0x00, 0x00, 0xFF, 0xFF,
	0x00, 0x00, 0x00, 0x00, 0x00, 0x00, 0x00, 0x00, 0x00, 0xF8, 0xF8, 0xF8, 0xF8, 0xF8, 0xF8, 0x00,
	0xFF, 0xFF, 0x00, 0x00, 0x00, 0x00, 0x00, 0x00, 0x00, 0x00, 0x00, 0x00, 0x00, 0x00, 0x00, 0x00,
	0x00, 0x00, 0x00, 0x00, 0x00, 0x00, 0x00, 0x00, 0x00, 0x00, 0x00, 0x00, 0x00, 0x00, 0x00, 0x00,
	0x00, 0x00, 0x00, 0x00, 0x00, 0x00, 0x00, 0x00, 0x00, 0x00, 0x00, 0x00, 0x00, 0x00, 0x00, 0x00,
	0x00, 0x00, 0x00, 0x00, 0x00, 0x00, 0x00, 0x00, 0x00, 0x00, 0x00, 0x00, 0x00, 0x00, 0xFF, 0xFF,
	0xC0, 0xC0, 0xC0, 0xC0, 0xC0, 0xC0, 0xC0, 0xC0, 0xC0, 0xC1, 0xC1, 0xC1, 0xC1, 0xC1, 0xC1, 0xC0,
	0xFF, 0xFF, 0x00, 0x00, 0x00, 0x00, 0x00, 0x00, 0x00, 0x00, 0x00, 0x00, 0x00, 0x00, 0x00, 0x00,
	0x00, 0x00, 0x00, 0x00, 0x00, 0x00, 0x00, 0x00, 0x00, 0x00, 0x00, 0x00, 0x00, 0x00, 0xFF, 0xFF,
	0xC0, 0xC0, 0xC0, 0xC0, 0xC0, 0xC0, 0xC0, 0xC0, 0xC0, 0xC1, 0xC1, 0xC1, 0xC1, 0xC1, 0xC1, 0xC0,
	0xFF, 0xFF, 0x00, 0x00, 0x00, 0x00, 0x00, 0x00, 0x00, 0x00, 0x00, 0x00, 0x00, 0x00, 0x00, 0x00,
	0x00, 0x00, 0x00, 0x00, 0x00, 0x00, 0x00, 0x00, 0x00, 0x00, 0x00, 0x00, 0x00, 0x00, 0x00, 0x00,
	0x00, 0x00, 0x00, 0x00, 0x00, 0x00, 0x00, 0x00, 0x00, 0x00, 0x00, 0x00, 0x00, 0x00, 0x00, 0x00,
	0x00, 0x00, 0x00, 0x00, 0x00, 0x00, 0x00, 0x00, 0x00, 0x00, 0x00, 0x00, 0x00, 0x00, 0x00, 0x00,
	0x00, 0x00, 0x00, 0x00, 0x00, 0x00, 0x00, 0x00, 0x00, 0x00, 0x00, 0x00, 0x00, 0x00, 0x00, 0x00,
	0x00, 0x00, 0x00, 0x00, 0x00, 0x00, 0x00, 0x00, 0x00, 0x00, 0x00, 0x00, 0x00, 0x00, 0x00, 0x00,
	0x00, 0x00, 0x00, 0x00, 0x00, 0x00, 0x00, 0x00, 0x00, 0x00, 0x00, 0x00, 0x00, 0x00, 0x00, 0x00,
	0x00, 0x00, 0x00, 0x00, 0x00, 0x00, 0x00, 0x00, 0x00, 0x00, 0x00, 0x00, 0x00, 0x00, 0x00, 0x00,
	0x00, 0x00, 0x00, 0x00, 0x00, 0x00, 0x00, 0x00, 0x00, 0x00, 0x00, 0x00, 0x00, 0x00, 0x00, 0x00,
	0x00, 0x00, 0x00, 0x00, 0x00, 0x00, 0x00, 0x00, 0x00, 0x00, 0x00, 0x00, 0x00, 0x00, 0x00, 0x00,
	0x00, 0x00, 0x00, 0x00, 0x00, 0x00, 0x00, 0x00, 0x00, 0x00, 0x00, 0x00, 0x00, 0x00, 0x00, 0x00,
	0x00, 0x00, 0x00, 0x00, 0x00, 0x00, 0x00, 0x00, 0x00, 0x00, 0x00, 0x00, 0x00, 0x00, 0x00, 0x00,
	0x00, 0x00, 0x00, 0x00, 0x00, 0x00, 0x00, 0x00, 0x00, 0x00, 0x00, 0x00, 0x00, 0x00, 0x00, 0x00,
	0x00, 0x00, 0x00, 0x00, 0x00, 0x00, 0x00, 0x00, 0x00, 0x00, 0x00, 0x00, 0x0C, 0x0C, 0x0C, 0x0C,
	0x0C, 0x0C, 0x0C, 0x0C, 0x00, 0x00, 0x00, 0x00, 0x00, 0x00, 0x00, 0x00, 0x00, 0x00, 0x00, 0x00,
	0x00, 0x00, 0x00, 0x00, 0x00, 0x00, 0x00, 0x00, 0x00, 0x00, 0x00, 0x00, 0x00, 0x00, 0x00, 0x00,
	0x00, 0x00, 0x00, 0x00, 0x00, 0x00, 0x00, 0x00, 0x00, 0x00, 0x00, 0x00, 0x00, 0x00, 0x00, 0x00,
	0x00, 0x00, 0x00, 0x00, 0x00, 0x00, 0x00, 0x00, 0x00, 0x00, 0x00, 0x00, 0x00, 0x00, 0x00, 0x00,
	0x00, 0x00, 0x00, 0x00, 0x00, 0x00, 0x00, 0x00, 0x00, 0x00, 0x00, 0x00, 0x00, 0x00, 0x00, 0x00,
	0x00, 0x00, 0x00, 0x00, 0x00, 0x00, 0x00, 0x00, 0x00, 0x00, 0x00, 0x00, 0x00, 0x00, 0x00, 0x00,
	0x00, 0x00, 0x00, 0x00, 0x00, 0x00, 0x00, 0x00, 0x00, 0x00, 0x00, 0x00, 0x00, 0x00, 0x00, 0x00,
	0x00, 0x00, 0x00, 0x00, 0x00, 0x00, 0x00, 0x00, 0x00, 0x00, 0x00, 0x00, 0x00, 0x00, 0x00, 0x00,
	0x00, 0x00, 0x00, 0x00, 0x00, 0x00, 0x00, 0x00, 0x00, 0x00, 0x00, 0x00, 0x00, 0x00, 0x00, 0x00,
	0x00, 0x00, 0x00, 0x00, 0x00, 0x00, 0x00, 0x00, 0x00, 0x00, 0x00, 0x00, 0x00, 0x00, 0x00, 0x00,
	0x00, 0x00, 0x00, 0x00, 0x00, 0x00, 0x00, 0x00, 0x00, 0x00, 0x00, 0x00, 0x00, 0x00, 0x00, 0x00,
	0x00, 0x00, 0x00, 0x00, 0x00, 0x00, 0x00, 0x00, 0x00, 0x00, 0x00, 0x00, 0x00, 0x00, 0x00, 0x00
};

const uint8_t OLED_DizzyBitmap[1024] = {
	0x00, 0x00, 0x00, 0x00, 0x00, 0x00, 0x00, 0x00, 0x00, 0x00, 0x00, 0x00, 0x00, 0x00, 0x00, 0x00,
	0x00, 0x00, 0x00, 0x00, 0x00, 0x00, 0x00, 0x00, 0x00, 0x00, 0x00, 0x00, 0x00, 0x00, 0x00, 0x00,
	0x00, 0x00, 0x00, 0x00, 0x00, 0x00, 0x00, 0x00, 0x00, 0x00, 0x00, 0x00, 0x00, 0x00, 0x00, 0x00,
	0x00, 0x00, 0x00, 0x00, 0x00, 0x00, 0x00, 0x00, 0x00, 0x00, 0x00, 0x00, 0x00, 0x00, 0x00, 0x00,
	0x00, 0x00, 0x00, 0x00, 0x00, 0x00, 0x00, 0x00, 0x00, 0x00, 0x00, 0x00, 0x00, 0x00, 0x00, 0x00,
	0x00, 0x00, 0x00, 0x00, 0x00, 0x00, 0x00, 0x00, 0x00, 0x00, 0x00, 0x00, 0x00, 0x00, 0x00, 0x00,
	0x00, 0x00, 0x00, 0x00, 0x00, 0x00, 0x00, 0x00, 0x00, 0x00, 0x00, 0x00, 0x00, 0x00, 0x00, 0x00,
	0x00, 0x00, 0x00, 0x00, 0x00, 0x00, 0x00, 0x00, 0x00, 0x00, 0x00, 0x00, 0x00, 0x00, 0x00, 0x00,
	0x00, 0x00, 0x00, 0x00, 0x00, 0x00, 0x00, 0x00, 0x00, 0x00, 0x00, 0x00, 0x00, 0x00, 0x00, 0x00,
	0x00, 0x00, 0x00, 0x00, 0x00, 0x00, 0x00, 0x00, 0x00, 0x00, 0x00, 0x00, 0x00, 0x00, 0x00, 0x00,
	0x00, 0x00, 0x00, 0x00, 0x00, 0x00, 0x00, 0x00, 0x00, 0x00, 0x00, 0x00, 0x00, 0x00, 0x00, 0x00,
	0x00, 0x00, 0x00, 0x00, 0x00, 0x00, 0x00, 0x00, 0x00, 0x00, 0x00, 0x00, 0x00, 0x00, 0x00, 0x00,
	0x00, 0x00, 0x00, 0x00, 0x00, 0x00, 0x00, 0x00, 0x00, 0x00, 0x00, 0x00, 0x00, 0x00, 0x00, 0x00,
	0x00, 0x00, 0x00, 0x00, 0x00, 0x00, 0x00, 0x00, 0x00, 0x00, 0x00, 0x00, 0x00, 0x00, 0x00, 0x00,
	0x00, 0x00, 0x00, 0x00, 0x00, 0x00, 0x00, 0x00, 0x00, 0x00, 0x00, 0x00, 0x00, 0x00, 0x00, 0x00,
	0x00, 0x00, 0x00, 0x00, 0x00, 0x00, 0x00, 0x00, 0x00, 0x00, 0x00, 0x00, 0x00, 0x00, 0x00, 0x00,
	0x00, 0x00, 0x00, 0x00, 0x00, 0x00, 0x00, 0x00, 0x00, 0x00, 0x00, 0x00, 0x00, 0x00, 0x00, 0x00,
	0x00, 0x00, 0x00, 0x00, 0x00, 0x00, 0x00, 0x00, 0x00, 0x00, 0x00, 0x00, 0x00, 0x00, 0x10, 0x30,
	0x60, 0xC0, 0x80, 0x00, 0x00, 0x00, 0x00, 0x00, 0x00, 0x00, 0x00, 0x00, 0x00, 0x00, 0x00, 0x80,
	0xC0, 0x60, 0x20, 0x00, 0x00, 0x00, 0x00, 0x00, 0x00, 0x00, 0x00, 0x00, 0x00, 0x00, 0x00, 0x00,
	0x00, 0x00, 0x00, 0x00, 0x00, 0x00, 0x00, 0x00, 0x00, 0x00, 0x00, 0x00, 0x00, 0x00, 0x10, 0x30,
	0x60, 0xC0, 0x80, 0x00, 0x00, 0x00, 0x00, 0x00, 0x00, 0x00, 0x00, 0x00, 0x00, 0x00, 0x00, 0x80,
	0xC0, 0x60, 0x20, 0x00, 0x00, 0x00, 0x00, 0x00, 0x00, 0x00, 0x00, 0x00, 0x00, 0x00, 0x00, 0x00,
	0x00, 0x00, 0x00, 0x00, 0x00, 0x00, 0x00, 0x00, 0x00, 0x00, 0x00, 0x00, 0x00, 0x00, 0x00, 0x00,
	0x00, 0x00, 0x00, 0x00, 0x00, 0x00, 0x00, 0x00, 0x00, 0x00, 0x00, 0x00, 0x00, 0x00, 0x00, 0x00,
	0x00, 0x00, 0x00, 0x00, 0x00, 0x00, 0x00, 0x00, 0x00, 0x00, 0x00, 0x00, 0x00, 0x00, 0x00, 0x00,
	0x00, 0x00, 0x01, 0x03, 0x06, 0x0C, 0x18, 0xB0, 0xE0, 0xE0, 0xB0, 0x18, 0x0C, 0x06, 0x03, 0x01,
	0x00, 0x00, 0x00, 0x00, 0x00, 0x00, 0x00, 0x00, 0x00, 0x00, 0x00, 0x00, 0x00, 0x00, 0x00, 0x00,
	0x00, 0x00, 0x00, 0x00, 0x00, 0x00, 0x00, 0x00, 0x00, 0x00, 0x00, 0x00, 0x00, 0x00, 0x00, 0x00,
	0x00, 0x00, 0x01, 0x03, 0x06, 0x0C, 0x18, 0xB0, 0xE0, 0xE0, 0xB0, 0x18, 0x0C, 0x06, 0x03, 0x01,
	0x00, 0x00, 0x00, 0x00, 0x00, 0x00, 0x00, 0x00, 0x00, 0x00, 0x00, 0x00, 0x00, 0x00, 0x00, 0x00,
	0x00, 0x00, 0x00, 0x00, 0x00, 0x00, 0x00, 0x00, 0x00, 0x00, 0x00, 0x00, 0x00, 0x00, 0x00, 0x00,
	0x00, 0x00, 0x00, 0x00, 0x00, 0x00, 0x00, 0x00, 0x00, 0x00, 0x00, 0x00, 0x00, 0x00, 0x00, 0x00,
	0x00, 0x00, 0x00, 0x00, 0x00, 0x00, 0x00, 0x00, 0x00, 0x00, 0x00, 0x00, 0x00, 0x00, 0x00, 0x80,
	0xC0, 0x60, 0x30, 0x18, 0x0C, 0x06, 0x03, 0x01, 0x00, 0x00, 0x01, 0x03, 0x06, 0x0C, 0x18, 0x30,
	0x60, 0xC0, 0x80, 0x00, 0x00, 0x00, 0x00, 0x00, 0x00, 0x00, 0x00, 0x00, 0x00, 0x00, 0x00, 0x00,
	0x00, 0x00, 0x00, 0x00, 0x00, 0x00, 0x00, 0x00, 0x00, 0x00, 0x00, 0x00, 0x00, 0x00, 0x00, 0x80,
	0xC0, 0x60, 0x30, 0x18, 0x0C, 0x06, 0x03, 0x01, 0x00, 0x00, 0x01, 0x03, 0x06, 0x0C, 0x18, 0x30,
	0x60, 0xC0, 0x80, 0x00, 0x00, 0x00, 0x00, 0x00, 0x00, 0x00, 0x00, 0x00, 0x00, 0x00, 0x00, 0x00,
	0x00, 0x00, 0x00, 0x00, 0x00, 0x00, 0x00, 0x00, 0x00, 0x00, 0x00, 0x00, 0x00, 0x00, 0x00, 0x00,
	0x00, 0x00, 0x00, 0x00, 0x00, 0x00, 0x00, 0x00, 0x00, 0x00, 0x00, 0x00, 0x00, 0x00, 0x00, 0x00,
	0x00, 0x00, 0x00, 0x00, 0x00, 0x00, 0x00, 0x00, 0x00, 0x00, 0x00, 0x00, 0x00, 0x00, 0x01, 0x01,
	0x00, 0x00, 0x00, 0x00, 0x00, 0x00, 0x00, 0x00, 0x00, 0x00, 0x00, 0x00, 0x00, 0x00, 0x00, 0x00,
	0x00, 0x00, 0x00, 0x00, 0x00, 0x00, 0x00, 0x00, 0x00, 0x00, 0x00, 0x00, 0x00, 0x00, 0x00, 0x00,
	0x00, 0x00, 0x00, 0x00, 0x00, 0x00, 0x00, 0x00, 0x00, 0x00, 0x00, 0x00, 0x00, 0x00, 0x01, 0x01,
	0x00, 0x00, 0x00, 0x00, 0x00, 0x00, 0x00, 0x00, 0x00, 0x00, 0x00, 0x00, 0x00, 0x00, 0x00, 0x00,
	0x00, 0x00, 0x00, 0x00, 0x00, 0x00, 0x00, 0x00, 0x00, 0x00, 0x00, 0x00, 0x00, 0x00, 0x00, 0x00,
	0x00, 0x00, 0x00, 0x00, 0x00, 0x00, 0x00, 0x00, 0x00, 0x00, 0x00, 0x00, 0x00, 0x00, 0x00, 0x00,
	0x00, 0x00, 0x00, 0x00, 0x00, 0x00, 0x00, 0x00, 0x00, 0x00, 0x00, 0x00, 0x00, 0x00, 0x00, 0x00,
	0x00, 0x00, 0x00, 0x00, 0x00, 0x00, 0x00, 0x00, 0x00, 0x00, 0x00, 0x00, 0x00, 0x00, 0x00, 0x00,
	0x00, 0x00, 0x00, 0x00, 0x00, 0x00, 0x00, 0x00, 0x00, 0x00, 0x00, 0x00, 0x00, 0x00, 0x00, 0x00,
	0x00, 0x00, 0x00, 0x00, 0x00, 0x00, 0x0C, 0x0C, 0x0C, 0x0C, 0x0C, 0x03, 0x03, 0x03, 0x03, 0x03,
	0x0C, 0x0C, 0x0C, 0x0C, 0x0C, 0x03, 0x03, 0x03, 0x03, 0x03, 0x00, 0x00, 0x00, 0x00, 0x00, 0x00,
	0x00, 0x00, 0x00, 0x00, 0x00, 0x00, 0x00, 0x00, 0x00, 0x00, 0x00, 0x00, 0x00, 0x00, 0x00, 0x00,
	0x00, 0x00, 0x00, 0x00, 0x00, 0x00, 0x00, 0x00, 0x00, 0x00, 0x00, 0x00, 0x00, 0x00, 0x00, 0x00,
	0x00, 0x00, 0x00, 0x00, 0x00, 0x00, 0x00, 0x00, 0x00, 0x00, 0x00, 0x00, 0x00, 0x00, 0x00, 0x00,
	0x00, 0x00, 0x00, 0x00, 0x00, 0x00, 0x00, 0x00, 0x00, 0x00, 0x00, 0x00, 0x00, 0x00, 0x00, 0x00,
	0x00, 0x00, 0x00, 0x00, 0x00, 0x00, 0x00, 0x00, 0x00, 0x00, 0x00, 0x00, 0x00, 0x00, 0x00, 0x00,
	0x00, 0x00, 0x00, 0x00, 0x00, 0x00, 0x00, 0x00, 0x00, 0x00, 0x00, 0x00, 0x00, 0x00, 0x00, 0x00,
	0x00, 0x00, 0x00, 0x00, 0x00, 0x00, 0x00, 0x00, 0x00, 0x00, 0x00, 0x00, 0x00, 0x00, 0x00, 0x00,
	0x00, 0x00, 0x00, 0x00, 0x00, 0x00, 0x00, 0x00, 0x00, 0x00, 0x00, 0x00, 0x00, 0x00, 0x00, 0x00,
	0x00, 0x00, 0x00, 0x00, 0x00, 0x00, 0x00, 0x00, 0x00, 0x00, 0x00, 0x00, 0x00, 0x00, 0x00, 0x00,
	0x00, 0x00, 0x00, 0x00, 0x00, 0x00, 0x00, 0x00, 0x00, 0x00, 0x00, 0x00, 0x00, 0x00, 0x00, 0x00
};
/* USER CODE END 0 */

int main(void)
{
  /* USER CODE BEGIN 1 */
    int pin_state = 1;
  /* USER CODE END 1 */

  /* MCU Configuration--------------------------------------------------------*/

  /* Reset of all peripherals, Initializes the Flash interface and the Systick. */
  HAL_Init();

  /* Configure the system clock */
  SystemClock_Config();

  /* Initialize all configured peripherals */
  MX_GPIO_Init();
  MX_USART2_UART_Init();
  MX_I2C1_Init();
  MX_TIM3_Init();
  MX_USART1_UART_Init();
  /* USER CODE BEGIN 2 */
    OLED_Init();
    OLED_Clear();

    // Start ESP32 UART Listener
    HAL_UART_Receive_IT(&huart1, &uart1_rx_byte, 1);

    // Start Motor PWM
    HAL_TIM_PWM_Start(&htim3, TIM_CHANNEL_1);
    HAL_TIM_PWM_Start(&htim3, TIM_CHANNEL_2);

    // Startup motor wiggle test to confirm operation
    set_motors(350, -350);
    HAL_Delay(150);
    set_motors(-350, 350);
    HAL_Delay(150);
    set_motors(0, 0);

    // Enable DWT Cycle Counter for HC-SR04 microsecond delays
    CoreDebug->DEMCR |= CoreDebug_DEMCR_TRCENA_Msk;
    DWT->CYCCNT = 0;
    DWT->CTRL |= DWT_CTRL_CYCCNTENA_Msk;

    // Wake up the ESP32 by pulling PC8 (connected to ESP32 Pin 14) HIGH
    HAL_GPIO_WritePin(GPIOC, GPIO_PIN_8, GPIO_PIN_SET);

    // Initialize SGP30
    SGP30_Init();

    uint8_t dev_id = 0;
    HAL_I2C_Mem_Read(&hi2c1, 0xA6, 0x00, I2C_MEMADD_SIZE_8BIT, &dev_id, 1, 100);

    uint8_t raw_data[6];
    int16_t x_accel, y_accel, z_accel;
    int16_t x_offset = 0, y_offset = 0, z_offset = 0;

    #define FILTER_DEPTH  8
    int16_t x_history[FILTER_DEPTH] = {0};
    int16_t y_history[FILTER_DEPTH] = {0};
    int16_t z_history[FILTER_DEPTH] = {0};
    uint8_t filter_idx = 0;

    if (dev_id == 0xE5) {
        printf("ADXL345 Logged On Successfully!\r\n");
        uint8_t power_ctl_data = 0x08;
        HAL_I2C_Mem_Write(&hi2c1, 0xA6, 0x2D, I2C_MEMADD_SIZE_8BIT, &power_ctl_data, 1, 100);
        HAL_Delay(100);

        HAL_I2C_Mem_Read(&hi2c1, 0xA6, 0x32, I2C_MEMADD_SIZE_8BIT, raw_data, 6, 100);
        x_offset = (int16_t)((raw_data[1] << 8) | raw_data[0]);
        y_offset = (int16_t)((raw_data[3] << 8) | raw_data[2]);
        z_offset = (int16_t)((raw_data[5] << 8) | raw_data[4]);

        printf("Calibrated! Offsets locked -> X:%d Y:%d Z:%d\r\n", x_offset, y_offset, z_offset);
        OLED_PrintText(0, 0, "CALIBRATED: OK ");
        HAL_Delay(1000);
        OLED_Clear();
    } else {
        printf("ADXL345 Handshake failed. Read ID: 0x%02X\r\n", dev_id);
        OLED_PrintText(0, 0, "SENSOR ERROR!");
    }
  /* USER CODE END 2 */

  /* Infinite loop */
  /* USER CODE BEGIN WHILE */
    static uint32_t last_toggle_time = 0;
        static uint32_t last_sgp_poll_time = 0;
        static uint32_t last_telemetry_send_time = 0;
        static uint16_t peak_co2 = 400;
        static uint16_t peak_tvoc = 0;
        static uint8_t display_mode = 1;      // 0 = Telemetry, 1 = Dog Canvas
        static uint8_t last_pin_state = 1;
        static uint8_t dynamic_refresh_needed = 1; // Tracks if static screens need a redraw pass
        static RobotEmotion last_rendered_emotion = EMOTION_HAPPY;
        static char wifi_status[32] = "IDLE";

        while (1)
        {
             uint32_t current_time = HAL_GetTick();

             // --- MOTOR SPEED RAMPING (Soft Start to prevent current surge / brownouts) ---
             static uint32_t last_ramp_time = 0;
             if (current_time - last_ramp_time >= 5) {
                 last_ramp_time = current_time;

                 // Ramp Left Speed
                 if (current_left_speed < target_left_speed) {
                     current_left_speed += 15;
                     if (current_left_speed > target_left_speed) current_left_speed = target_left_speed;
                 } else if (current_left_speed > target_left_speed) {
                     current_left_speed -= 15;
                     if (current_left_speed < target_left_speed) current_left_speed = target_left_speed;
                 }

                 // Ramp Right Speed
                 if (current_right_speed < target_right_speed) {
                     current_right_speed += 15;
                     if (current_right_speed > target_right_speed) current_right_speed = target_right_speed;
                 } else if (current_right_speed > target_right_speed) {
                     current_right_speed -= 15;
                     if (current_right_speed < target_right_speed) current_right_speed = target_right_speed;
                 }

                 // Apply current ramped speeds physically
                 apply_motors(current_left_speed, current_right_speed);
             }

             // --- PARSE INCOMING COMMANDS FROM ESP32 ---
             if (cmd_rx_ready == 1) {
                 cmd_rx_ready = 0;
                 char local_cmd_buf[256];
                 __HAL_UART_DISABLE_IT(&huart1, UART_IT_RXNE);
                 strncpy(local_cmd_buf, (char*)cmd_rx_buffer, sizeof(local_cmd_buf) - 1);
                 local_cmd_buf[sizeof(local_cmd_buf) - 1] = '\0';
                 __HAL_UART_ENABLE_IT(&huart1, UART_IT_RXNE);

                 // Strip trailing \r or \n
                 int cmd_len = strlen(local_cmd_buf);
                 while (cmd_len > 0 && (local_cmd_buf[cmd_len - 1] == '\r' || local_cmd_buf[cmd_len - 1] == '\n')) {
                     local_cmd_buf[cmd_len - 1] = '\0';
                     cmd_len--;
                 }

                 if (strncmp(local_cmd_buf, "WIFISTATUS:", 11) == 0) {
                     char* status_ptr = local_cmd_buf + 11;
                     if (strncmp(status_ptr, "CONNECTING", 10) == 0) {
                         char* comma_ptr = strchr(status_ptr, ',');
                         if (comma_ptr != NULL) {
                             snprintf(wifi_status, sizeof(wifi_status), "CONN: %s", comma_ptr + 1);
                         } else {
                             strncpy(wifi_status, "CONNECTING...", sizeof(wifi_status) - 1);
                         }
                     } else if (strcmp(status_ptr, "CONNECTED") == 0) {
                         strncpy(wifi_status, "CONNECTED", sizeof(wifi_status) - 1);
                      } else if (strcmp(status_ptr, "FAILED") == 0) {
                          strncpy(wifi_status, "CONN FAILED", sizeof(wifi_status) - 1);
                      }
                      dynamic_refresh_needed = 1;
                  } else if (strncmp(local_cmd_buf, "MOTOR:", 6) == 0) {
                      int left = 0, right = 0;
                      if (sscanf(local_cmd_buf, "MOTOR:%d,%d", &left, &right) == 2) {
                          manual_left_speed = left;
                          manual_right_speed = right;
                          last_manual_command_time = HAL_GetTick();
                          printf("[DEBUG] MOTOR RX - Left: %d, Right: %d\r\n", left, right);
                      }
                  }
             }

             // 1. Read the Bumper (HC-SR04) every 100ms instead of every loop cycle to prevent CPU blocking
             static uint32_t last_bumper_time = 0;
             static int distance = 0;
             if (current_time - last_bumper_time >= 100) {
                 last_bumper_time = current_time;
                 distance = HCSR04_Read();
             }

            // 2. Evaluate Emotion State Machine / Motor Control
            if (current_time - last_manual_command_time < 800) {
                // Manual override from webpage is active
                set_motors(manual_left_speed, manual_right_speed);
                current_emotion = EMOTION_HAPPY;
            } else {
                // Autonomous mode
                if (current_time - last_bop_time < 3000) {
                    current_emotion = EMOTION_DIZZY;
                    set_motors(0, 0);
                } else if (distance > 0 && distance < 15) {
                    current_emotion = EMOTION_ANGRY;
                    set_motors(0, 0);
                } else if (current_time - last_face_time > 10000) {
                    current_emotion = EMOTION_SEARCHING;
                    set_motors(0, 0);
                } else {
                    current_emotion = EMOTION_HAPPY;
                    track_face();
                }
            }

            // 3. Trigger Screen Refresh on Emotion Change
            if (display_mode == 1 && last_rendered_emotion != current_emotion) {
                last_rendered_emotion = current_emotion;
                dynamic_refresh_needed = 1;
            }

            // Poll Air Quality every 1 second to capture fast transient odors
            if (current_time - last_sgp_poll_time >= 1000) {
                last_sgp_poll_time = current_time;

                uint16_t cur_co2 = 400;
                uint16_t cur_tvoc = 0;
                SGP30_Measure(&cur_co2, &cur_tvoc);

                // Update the peak values detected during this transmit window
                if (cur_co2 > peak_co2) peak_co2 = cur_co2;
                if (cur_tvoc > peak_tvoc) peak_tvoc = cur_tvoc;
            }

            // Transmit peak telemetry data to AWS/ESP32 every 5 seconds to stay inside Free Tier limits
            if (current_time - last_telemetry_send_time >= 5000) {
                last_telemetry_send_time = current_time;

                // Set the global variables for OLED screen rendering and debugging
                sgp30_co2 = peak_co2;
                sgp30_tvoc = peak_tvoc;

                // Transmit Telemetry over UART to ESP32
                char tele_buf[64];
                int len = snprintf(tele_buf, sizeof(tele_buf), "TELEMETRY:%d,%d,%d,%d\n", sgp30_co2, sgp30_tvoc, distance, current_emotion);
                HAL_StatusTypeDef status = HAL_UART_Transmit(&huart1, (uint8_t*)tele_buf, len, 100);

                // Also print to USART2 (Virtual COM Port) for PC serial debugging
                // printf("Nucleo UART TX Status: %d (0=OK, 1=BUSY, 2=ERROR), Distance: %d\r\n", status, distance);

                // Reset peak values for the next window
                peak_co2 = 400;
                peak_tvoc = 0;
            }

            // --- MENU BUTTON TOGGLE / DETECT OPTION LOGIC ---
            uint8_t pin_read = HAL_GPIO_ReadPin(GPIOC, GPIO_PIN_13);
            if (pin_read == 0 && last_pin_state == 1) {
                button_pressed_time = HAL_GetTick();
                button_held = 1;
                HAL_Delay(50); // Button debounce
            } else if (pin_read == 1 && last_pin_state == 0) {
                if (button_held) {
                    button_held = 0;
                    uint32_t press_duration = HAL_GetTick() - button_pressed_time;
                    if (press_duration < 800) {
                        // Short press: Cycle display modes (0 -> 1 -> 2 -> 0)
                        display_mode = (display_mode + 1) % 3;
                        OLED_Clear();
                        dynamic_refresh_needed = 1;
                        last_toggle_time = 0;
                    }
                }
            }

            // Check for active long press to toggle pin state (when in display_mode == 2)
            if (button_held && (HAL_GetTick() - button_pressed_time >= 800)) {
                button_held = 0; // Trigger once per hold
                if (display_mode == 2) {
                    face_detect_pin_state = !face_detect_pin_state;
                    HAL_GPIO_WritePin(GPIOC, GPIO_PIN_8, face_detect_pin_state ? GPIO_PIN_SET : GPIO_PIN_RESET);
                    OLED_Clear();
                    dynamic_refresh_needed = 1;
                }
            }
            last_pin_state = pin_read;

            // Everything inside here executes exactly once every 200ms
            if (current_time - last_toggle_time >= 200)
            {

                if (dev_id == 0xE5) {
                    // Keep reading sensor data dynamically regardless of display view state
                    HAL_I2C_Mem_Read(&hi2c1, 0xA6, 0x32, I2C_MEMADD_SIZE_8BIT, raw_data, 6, 100);

                    int16_t raw_x = (int16_t)((raw_data[1] << 8) | raw_data[0]);
                    int16_t raw_y = (int16_t)((raw_data[3] << 8) | raw_data[2]);
                    int16_t raw_z = (int16_t)((raw_data[5] << 8) | raw_data[4]);

                    x_accel = raw_x - x_offset;
                    y_accel = raw_y - y_offset;
                    z_accel = raw_z - z_offset;

                    // BOP DETECTOR (Trigger Dizzy Emotion based on sudden delta/jerk to ignore gravity)
                    static int16_t prev_x = 0, prev_y = 0;
                    int16_t delta_x = x_accel - prev_x;
                    int16_t delta_y = y_accel - prev_y;

                    if (delta_x > 150 || delta_x < -150 || delta_y > 150 || delta_y < -150) {
                        last_bop_time = HAL_GetTick();
                    }
                    prev_x = x_accel;
                    prev_y = y_accel;

                    x_history[filter_idx] = x_accel;
                    y_history[filter_idx] = y_accel;
                    z_history[filter_idx] = z_accel;
                    filter_idx = (filter_idx + 1) % FILTER_DEPTH;

                    int32_t x_sum = 0, y_sum = 0, z_sum = 0;
                    for (int i = 0; i < FILTER_DEPTH; i++) {
                        x_sum += x_history[i];
                        y_sum += y_history[i];
                        z_sum += z_history[i];
                    }

                    int16_t x_smooth = x_sum / FILTER_DEPTH;
                    int16_t y_smooth = y_sum / FILTER_DEPTH;
                    int16_t z_smooth = z_sum / FILTER_DEPTH;
                    if (face_detected) {
                         // printf("[STATUS] Tracking Face at X:%d | Rx:%lu | Air: CO2 %dppm TVOC %dppb | Tilt: %d\r\n", target_face_x, uart_rx_count, sgp30_co2, sgp30_tvoc, x_smooth);
                    } else {
                         // printf("[STATUS] Idle | Rx:%lu | Air: CO2 %dppm TVOC %dppb | Tilt: %d\r\n", uart_rx_count, sgp30_co2, sgp30_tvoc, x_smooth);
                    }
                    if (display_mode == 0) {
                        // MODE 0: Active Telemetry
                        if (dynamic_refresh_needed) {
                            OLED_PrintText(0, 0, "SYSTEM RUNNING!     ");
                            char wifi_line[21];
                            snprintf(wifi_line, sizeof(wifi_line), "WIFI: %-14.14s", wifi_status);
                            OLED_PrintText(1, 0, wifi_line);
                            OLED_PrintText(2, 0, "TILT X:             ");
                            OLED_PrintText(4, 0, "CO2:                ");
                            OLED_PrintText(6, 0, "TVOC:               ");
                            dynamic_refresh_needed = 0;
                        }

                        char display_buffer[24];
                        sprintf(display_buffer, "%d      ", x_smooth);
                        OLED_PrintText(2, 48, display_buffer);

                        sprintf(display_buffer, "%d ppm   ", sgp30_co2);
                        OLED_PrintText(4, 48, display_buffer);

                        sprintf(display_buffer, "%d ppb   ", sgp30_tvoc);
                        OLED_PrintText(6, 48, display_buffer);
                    }
                    else if (display_mode == 1) {
                        // MODE 1: Draw dynamic emotional canvas
                        static uint32_t last_anim_tick = 0;
                        static int anim_frame = 0;

                        if (current_emotion == EMOTION_SEARCHING) {
                            if (current_time - last_anim_tick > 500) {
                                last_anim_tick = current_time;
                                anim_frame = (anim_frame + 1) % 4;
                                dynamic_refresh_needed = 1;
                            }
                        }

                        if (dynamic_refresh_needed) {
                            if (current_emotion == EMOTION_HAPPY) {
                                OLED_DrawBitmap(OLED_SmileBitmap);
                            } else if (current_emotion == EMOTION_ANGRY) {
                                OLED_DrawBitmap(OLED_AngryBitmap);
                            } else if (current_emotion == EMOTION_SEARCHING) {
                                if (anim_frame == 0) OLED_DrawBitmap(OLED_LookLeftBitmap);
                                else if (anim_frame == 1 || anim_frame == 3) OLED_DrawBitmap(OLED_LookCenterBitmap);
                                else OLED_DrawBitmap(OLED_LookRightBitmap);
                            } else if (current_emotion == EMOTION_DIZZY) {
                                OLED_DrawBitmap(OLED_DizzyBitmap);
                            }
                            dynamic_refresh_needed = 0;
                        }
                    }
                    else if (display_mode == 2) {
                        // MODE 2: Options Menu
                        if (dynamic_refresh_needed) {
                            OLED_PrintText(0, 0, "=== SCREEN MENU ===");
                            OLED_PrintText(2, 0, "Face Detect Pin:    ");
                            if (face_detect_pin_state) {
                                OLED_PrintText(2, 96, "[ON] ");
                            } else {
                                OLED_PrintText(2, 96, "[OFF]");
                            }
                            OLED_PrintText(4, 0, "* Hold Blue Button  ");
                            OLED_PrintText(5, 0, "  for 1s to toggle  ");
                            dynamic_refresh_needed = 0;
                        }
                    }
                    }
                last_toggle_time = current_time;
            }

            // --- EMOTION-BASED USER LED PATTERNS ---
            static uint32_t last_led_time = 0;
            uint32_t led_interval = 500; // Default: slow 500ms blink

            if (current_emotion == EMOTION_DIZZY) {
                led_interval = 50;  // Dizzy ➔ Rapid 50ms strobe!
            } else if (current_emotion == EMOTION_ANGRY) {
                led_interval = 100; // Angry ➔ Fast 100ms warning flash!
            } else if (current_emotion == EMOTION_HAPPY) {
                // Happy (Target Locked) ➔ Solid ON!
                HAL_GPIO_WritePin(GPIOA, GPIO_PIN_5, GPIO_PIN_SET);
                led_interval = 0; // Disable toggling
            } else {
                // Searching/Idle ➔ Slow double-blink (heartbeat: 100ms on, 100ms off, 100ms on, 700ms off)
                uint32_t cycle = current_time % 1000;
                if (cycle < 100 || (cycle >= 200 && cycle < 300)) {
                    HAL_GPIO_WritePin(GPIOA, GPIO_PIN_5, GPIO_PIN_SET);
                } else {
                    HAL_GPIO_WritePin(GPIOA, GPIO_PIN_5, GPIO_PIN_RESET);
                }
                led_interval = 0; // Disable toggling
            }

            if (led_interval > 0 && current_time - last_led_time >= led_interval) {
                last_led_time = current_time;
                HAL_GPIO_TogglePin(GPIOA, GPIO_PIN_5);
            }
    /* USER CODE END WHILE */

    }
}

void SystemClock_Config(void)
{
  RCC_OscInitTypeDef RCC_OscInitStruct = {0};
  RCC_ClkInitTypeDef RCC_ClkInitStruct = {0};

  /** Configure the main internal regulator output voltage
  */
  __HAL_RCC_PWR_CLK_ENABLE();
  __HAL_PWR_VOLTAGESCALING_CONFIG(PWR_REGULATOR_VOLTAGE_SCALE1);

  /** Initializes the RCC Oscillators according to the specified parameters
  * in the RCC_OscInitTypeDef structure.
  */
  RCC_OscInitStruct.OscillatorType = RCC_OSCILLATORTYPE_HSI;
  RCC_OscInitStruct.HSIState = RCC_HSI_ON;
  RCC_OscInitStruct.HSICalibrationValue = RCC_HSICALIBRATION_DEFAULT;
  RCC_OscInitStruct.PLL.PLLState = RCC_PLL_NONE;
  if (HAL_RCC_OscConfig(&RCC_OscInitStruct) != HAL_OK)
  {
    Error_Handler();
  }

  /** Initializes the CPU, AHB and APB buses clocks
  */
  RCC_ClkInitStruct.ClockType = RCC_CLOCKTYPE_HCLK|RCC_CLOCKTYPE_SYSCLK
                              |RCC_CLOCKTYPE_PCLK1|RCC_CLOCKTYPE_PCLK2;
  RCC_ClkInitStruct.SYSCLKSource = RCC_SYSCLKSOURCE_HSI;
  RCC_ClkInitStruct.AHBCLKDivider = RCC_SYSCLK_DIV1;
  RCC_ClkInitStruct.APB1CLKDivider = RCC_HCLK_DIV1;
  RCC_ClkInitStruct.APB2CLKDivider = RCC_HCLK_DIV1;

  if (HAL_RCC_ClockConfig(&RCC_ClkInitStruct, FLASH_LATENCY_0) != HAL_OK)
  {
    Error_Handler();
  }
}

static void MX_I2C1_Init(void)
{

  hi2c1.Instance = I2C1;
  hi2c1.Init.ClockSpeed = 400000;
  hi2c1.Init.DutyCycle = I2C_DUTYCYCLE_2;
  hi2c1.Init.OwnAddress1 = 0;
  hi2c1.Init.AddressingMode = I2C_ADDRESSINGMODE_7BIT;
  hi2c1.Init.DualAddressMode = I2C_DUALADDRESS_DISABLE;
  hi2c1.Init.OwnAddress2 = 0;
  hi2c1.Init.GeneralCallMode = I2C_GENERALCALL_DISABLE;
  hi2c1.Init.NoStretchMode = I2C_NOSTRETCH_DISABLE;
  if (HAL_I2C_Init(&hi2c1) != HAL_OK)
  {
    Error_Handler();
  }

}

static void MX_TIM3_Init(void)
{

  TIM_ClockConfigTypeDef sClockSourceConfig = {0};
  TIM_MasterConfigTypeDef sMasterConfig = {0};
  TIM_OC_InitTypeDef sConfigOC = {0};

  htim3.Instance = TIM3;
  htim3.Init.Prescaler = 0;
  htim3.Init.CounterMode = TIM_COUNTERMODE_UP;
  htim3.Init.Period = 65535;
  htim3.Init.ClockDivision = TIM_CLOCKDIVISION_DIV1;
  htim3.Init.AutoReloadPreload = TIM_AUTORELOAD_PRELOAD_DISABLE;
  if (HAL_TIM_Base_Init(&htim3) != HAL_OK)
  {
    Error_Handler();
  }
  sClockSourceConfig.ClockSource = TIM_CLOCKSOURCE_INTERNAL;
  if (HAL_TIM_ConfigClockSource(&htim3, &sClockSourceConfig) != HAL_OK)
  {
    Error_Handler();
  }
  if (HAL_TIM_PWM_Init(&htim3) != HAL_OK)
  {
    Error_Handler();
  }
  sMasterConfig.MasterOutputTrigger = TIM_TRGO_RESET;
  sMasterConfig.MasterSlaveMode = TIM_MASTERSLAVEMODE_DISABLE;
  if (HAL_TIMEx_MasterConfigSynchronization(&htim3, &sMasterConfig) != HAL_OK)
  {
    Error_Handler();
  }
  sConfigOC.OCMode = TIM_OCMODE_PWM1;
  sConfigOC.Pulse = 0;
  sConfigOC.OCPolarity = TIM_OCPOLARITY_HIGH;
  sConfigOC.OCFastMode = TIM_OCFAST_DISABLE;
  if (HAL_TIM_PWM_ConfigChannel(&htim3, &sConfigOC, TIM_CHANNEL_1) != HAL_OK)
  {
    Error_Handler();
  }
  if (HAL_TIM_PWM_ConfigChannel(&htim3, &sConfigOC, TIM_CHANNEL_2) != HAL_OK)
  {
    Error_Handler();
  }
  HAL_TIM_MspPostInit(&htim3);

}

static void MX_USART1_UART_Init(void)
{

  huart1.Instance = USART1;
  huart1.Init.BaudRate = 115200;
  huart1.Init.WordLength = UART_WORDLENGTH_8B;
  huart1.Init.StopBits = UART_STOPBITS_1;
  huart1.Init.Parity = UART_PARITY_NONE;
  huart1.Init.Mode = UART_MODE_TX_RX;
  huart1.Init.HwFlowCtl = UART_HWCONTROL_NONE;
  huart1.Init.OverSampling = UART_OVERSAMPLING_16;
  if (HAL_UART_Init(&huart1) != HAL_OK)
  {
    Error_Handler();
  }

}

static void MX_USART2_UART_Init(void)
{

  huart2.Instance = USART2;
  huart2.Init.BaudRate = 115200;
  huart2.Init.WordLength = UART_WORDLENGTH_8B;
  huart2.Init.StopBits = UART_STOPBITS_1;
  huart2.Init.Parity = UART_PARITY_NONE;
  huart2.Init.Mode = UART_MODE_TX_RX;
  huart2.Init.HwFlowCtl = UART_HWCONTROL_NONE;
  huart2.Init.OverSampling = UART_OVERSAMPLING_16;
  if (HAL_UART_Init(&huart2) != HAL_OK)
  {
    Error_Handler();
  }

}

static void MX_GPIO_Init(void)
{
  GPIO_InitTypeDef GPIO_InitStruct = {0};

  /* GPIO Ports Clock Enable */
  __HAL_RCC_GPIOC_CLK_ENABLE();
  __HAL_RCC_GPIOA_CLK_ENABLE();
  __HAL_RCC_GPIOB_CLK_ENABLE();

  /*Configure GPIO pin Output Level */
  HAL_GPIO_WritePin(GPIOA, GPIO_PIN_5|GPIO_PIN_8, GPIO_PIN_RESET);

  /*Configure GPIO pin Output Level */
  HAL_GPIO_WritePin(GPIOB, GPIO_PIN_1|GPIO_PIN_13|GPIO_PIN_14|GPIO_PIN_15, GPIO_PIN_RESET);

  /*Configure GPIO pin Output Level */
  HAL_GPIO_WritePin(GPIOC, GPIO_PIN_8, GPIO_PIN_RESET);

  /*Configure GPIO pins : PC13 PC7 */
  GPIO_InitStruct.Pin = GPIO_PIN_13|GPIO_PIN_7;
  GPIO_InitStruct.Mode = GPIO_MODE_INPUT;
  GPIO_InitStruct.Pull = GPIO_NOPULL;
  HAL_GPIO_Init(GPIOC, &GPIO_InitStruct);

  /*Configure GPIO pins : PA5 PA8 */
  GPIO_InitStruct.Pin = GPIO_PIN_5|GPIO_PIN_8;
  GPIO_InitStruct.Mode = GPIO_MODE_OUTPUT_PP;
  GPIO_InitStruct.Pull = GPIO_NOPULL;
  GPIO_InitStruct.Speed = GPIO_SPEED_FREQ_LOW;
  HAL_GPIO_Init(GPIOA, &GPIO_InitStruct);

  /*Configure GPIO pins : PB1 PB13 PB14 PB15 */
  GPIO_InitStruct.Pin = GPIO_PIN_1|GPIO_PIN_13|GPIO_PIN_14|GPIO_PIN_15;
  GPIO_InitStruct.Mode = GPIO_MODE_OUTPUT_PP;
  GPIO_InitStruct.Pull = GPIO_NOPULL;
  GPIO_InitStruct.Speed = GPIO_SPEED_FREQ_LOW;
  HAL_GPIO_Init(GPIOB, &GPIO_InitStruct);

  /*Configure GPIO pin : PC8 */
  GPIO_InitStruct.Pin = GPIO_PIN_8;
  GPIO_InitStruct.Mode = GPIO_MODE_OUTPUT_PP;
  GPIO_InitStruct.Pull = GPIO_NOPULL;
  GPIO_InitStruct.Speed = GPIO_SPEED_FREQ_LOW;
  HAL_GPIO_Init(GPIOC, &GPIO_InitStruct);

}

/* USER CODE BEGIN 4 */
void HAL_UART_RxCpltCallback(UART_HandleTypeDef *huart) {
    if (huart->Instance == USART1) {
        uart_rx_count++;
        if (uart1_rx_byte == '\n') {
            esp32_rx_buffer[esp32_rx_index] = '\0';
            int id, x, y;
            if (sscanf(esp32_rx_buffer, "FACE:%d,%d,%d", &id, &x, &y) == 3) {
                if (id >= -1) {
                    face_detected = 1;
                    target_face_x = x;
                    target_face_y = y;
                    last_face_time = HAL_GetTick();
                } else if (id == -2) {
                    face_detected = 0;
                }
            } else {
                // Buffer non-face commands for main loop processing
                strncpy((char*)cmd_rx_buffer, esp32_rx_buffer, sizeof(cmd_rx_buffer) - 1);
                cmd_rx_buffer[sizeof(cmd_rx_buffer) - 1] = '\0';
                cmd_rx_ready = 1;
            }
            esp32_rx_index = 0;
        } else {
            if (esp32_rx_index < 255) {
                esp32_rx_buffer[esp32_rx_index++] = uart1_rx_byte;
            }
        }
        HAL_UART_Receive_IT(&huart1, &uart1_rx_byte, 1);
    }
}

void HAL_UART_ErrorCallback(UART_HandleTypeDef *huart) {
    if (huart->Instance == USART1) {
        // Clear Overrun Error flag and re-arm interrupt
        __HAL_UART_CLEAR_OREFLAG(huart);
        HAL_UART_Receive_IT(&huart1, &uart1_rx_byte, 1);
    }
}

#ifdef __GNUC__
#define PUTCHAR_PROTOTYPE int __io_putchar(int ch)
#else
#define PUTCHAR_PROTOTYPE int fputc(int ch, FILE *f)
#endif
PUTCHAR_PROTOTYPE {
  HAL_UART_Transmit(&huart2, (uint8_t *)&ch, 1, 10);
  return ch;
}
/* USER CODE END 4 */

void Error_Handler(void)
{
  __disable_irq();
  while (1)
  {
  }
}
